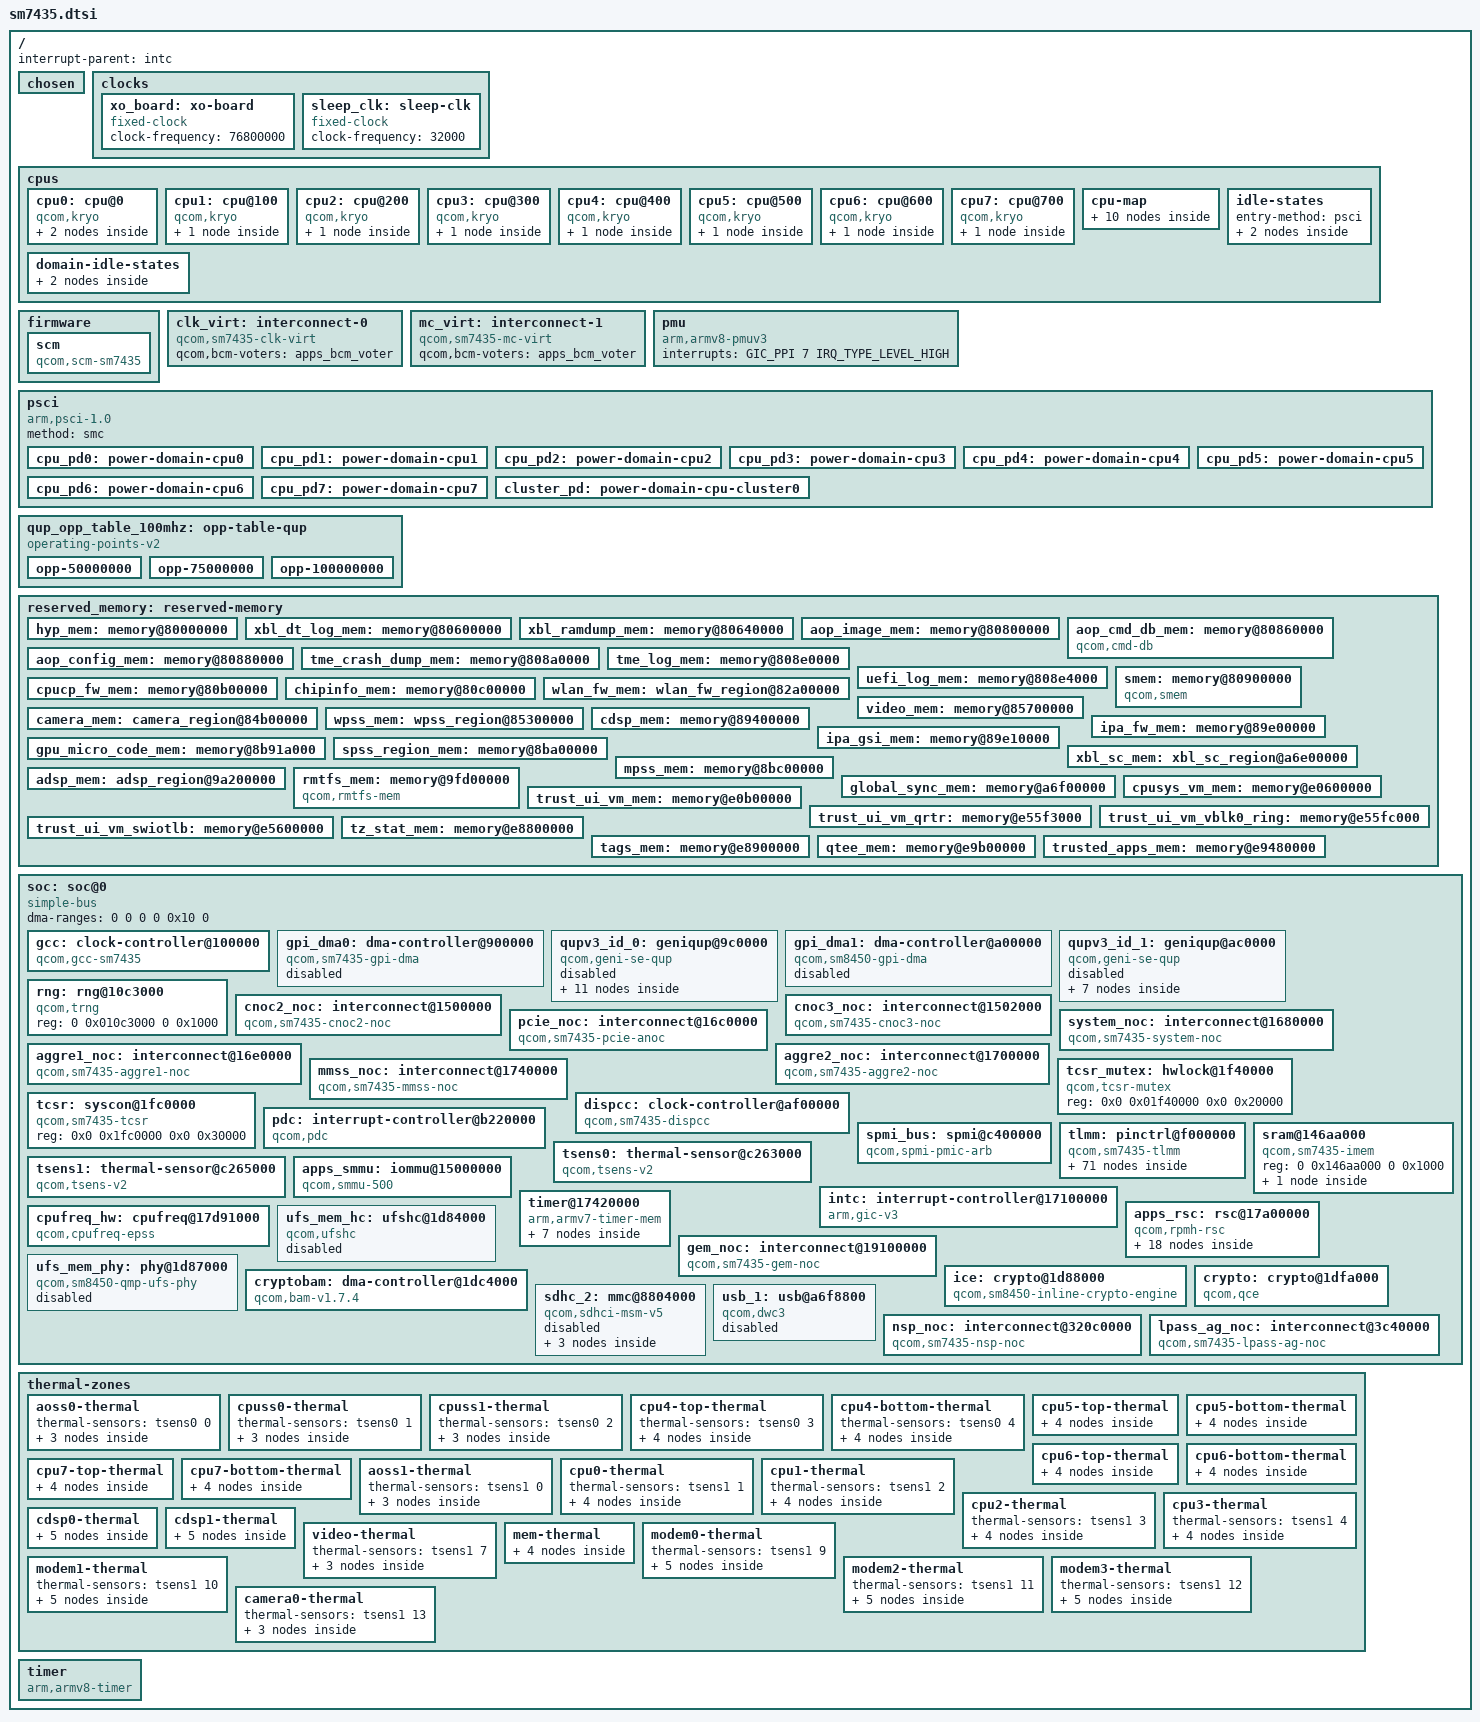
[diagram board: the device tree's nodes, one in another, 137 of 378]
// SPDX-License-Identifier: BSD-3-Clause
/*
 * Copyright (c) 2025 Artur Weber <aweber.kernel@gmail.com>
 */

#include <dt-bindings/interrupt-controller/arm-gic.h>
#include <dt-bindings/clock/qcom,gcc-sm7435.h>
#include <dt-bindings/clock/qcom,rpmh.h>
#include <dt-bindings/clock/qcom,sm7435-dispcc.h>
#include <dt-bindings/gpio/gpio.h>
#include <dt-bindings/mailbox/qcom-ipcc.h>
#include <dt-bindings/power/qcom,rpmhpd.h>
#include <dt-bindings/power/qcom-rpmpd.h>
#include <dt-bindings/interconnect/qcom,icc.h>
#include <dt-bindings/interconnect/qcom,sm7435.h>
#include <dt-bindings/soc/qcom,rpmh-rsc.h>
#include <dt-bindings/firmware/qcom,scm.h>
#include <dt-bindings/dma/qcom-gpi.h>

/ {
	interrupt-parent = <&intc>;

	#address-cells = <2>;
	#size-cells = <2>;

	chosen { };

	clocks {
		xo_board: xo-board {
			compatible = "fixed-clock";
			#clock-cells = <0>;
			clock-frequency = <76800000>;
		};

		sleep_clk: sleep-clk {
			compatible = "fixed-clock";
			#clock-cells = <0>;
			clock-frequency = <32000>; // TODO: 32764?
		};
	};

	cpus {
		#address-cells = <2>;
		#size-cells = <0>;

		// TODO: cache-unified? Should be fine but drop if it causes problems
		cpu0: cpu@0 {
			device_type = "cpu";
			compatible = "qcom,kryo";
			reg = <0x0 0x0>;
			enable-method = "psci";
			next-level-cache = <&l2_0>;
			power-domains = <&cpu_pd0>;
			power-domain-names = "psci";
			qcom,freq-domain = <&cpufreq_hw 0>;
			#cooling-cells = <2>;
			clocks = <&cpufreq_hw 0>;
			l2_0: l2-cache {
				compatible = "cache";
				cache-level = <2>;
				cache-unified;
				next-level-cache = <&l3_0>;
				l3_0: l3-cache {
					compatible = "cache";
					cache-level = <3>;
					cache-unified;
				};
			};
		};

		cpu1: cpu@100 {
			device_type = "cpu";
			compatible = "qcom,kryo";
			reg = <0x0 0x100>;
			enable-method = "psci";
			next-level-cache = <&l2_100>;
			power-domains = <&cpu_pd1>;
			power-domain-names = "psci";
			qcom,freq-domain = <&cpufreq_hw 0>;
			#cooling-cells = <2>;
			clocks = <&cpufreq_hw 0>;
			l2_100: l2-cache {
				compatible = "cache";
				cache-level = <2>;
				cache-unified;
				next-level-cache = <&l3_0>;
			};
		};

		cpu2: cpu@200 {
			device_type = "cpu";
			compatible = "qcom,kryo";
			reg = <0x0 0x200>;
			enable-method = "psci";
			next-level-cache = <&l2_200>;
			power-domains = <&cpu_pd2>;
			power-domain-names = "psci";
			qcom,freq-domain = <&cpufreq_hw 0>;
			#cooling-cells = <2>;
			clocks = <&cpufreq_hw 0>;
			l2_200: l2-cache {
				compatible = "cache";
				cache-level = <2>;
				cache-unified;
				next-level-cache = <&l3_0>;
			};
		};

		cpu3: cpu@300 {
			device_type = "cpu";
			compatible = "qcom,kryo";
			reg = <0x0 0x300>;
			enable-method = "psci";
			next-level-cache = <&l2_300>;
			power-domains = <&cpu_pd3>;
			power-domain-names = "psci";
			qcom,freq-domain = <&cpufreq_hw 0>;
			#cooling-cells = <2>;
			clocks = <&cpufreq_hw 0>;
			l2_300: l2-cache {
				compatible = "cache";
				cache-level = <2>;
				cache-unified;
				next-level-cache = <&l3_0>;
			};
		};

		cpu4: cpu@400 {
			device_type = "cpu";
			compatible = "qcom,kryo";
			reg = <0x0 0x400>;
			enable-method = "psci";
			next-level-cache = <&l2_400>;
			power-domains = <&cpu_pd4>;
			power-domain-names = "psci";
			qcom,freq-domain = <&cpufreq_hw 1>;
			#cooling-cells = <2>;
			clocks = <&cpufreq_hw 1>;
			l2_400: l2-cache {
				compatible = "cache";
				cache-level = <2>;
				cache-unified;
				next-level-cache = <&l3_0>;
			};
		};

		cpu5: cpu@500 {
			device_type = "cpu";
			compatible = "qcom,kryo";
			reg = <0x0 0x500>;
			enable-method = "psci";
			next-level-cache = <&l2_500>;
			power-domains = <&cpu_pd5>;
			power-domain-names = "psci";
			qcom,freq-domain = <&cpufreq_hw 1>;
			#cooling-cells = <2>;
			clocks = <&cpufreq_hw 1>;
			l2_500: l2-cache {
				compatible = "cache";
				cache-level = <2>;
				cache-unified;
				next-level-cache = <&l3_0>;
			};
		};

		cpu6: cpu@600 {
			device_type = "cpu";
			compatible = "qcom,kryo";
			reg = <0x0 0x600>;
			enable-method = "psci";
			next-level-cache = <&l2_600>;
			power-domains = <&cpu_pd6>;
			power-domain-names = "psci";
			qcom,freq-domain = <&cpufreq_hw 1>;
			#cooling-cells = <2>;
			clocks = <&cpufreq_hw 1>;
			l2_600: l2-cache {
				compatible = "cache";
				cache-level = <2>;
				cache-unified;
				next-level-cache = <&l3_0>;
			};
		};

		cpu7: cpu@700 {
			device_type = "cpu";
			compatible = "qcom,kryo";
			reg = <0x0 0x700>;
			enable-method = "psci";
			next-level-cache = <&l2_700>;
			power-domains = <&cpu_pd7>;
			power-domain-names = "psci";
			qcom,freq-domain = <&cpufreq_hw 2>;
			#cooling-cells = <2>;
			clocks = <&cpufreq_hw 2>;
			l2_700: l2-cache {
				compatible = "cache";
				cache-level = <2>;
				cache-unified;
				next-level-cache = <&l3_0>;
			};
		};

		cpu-map {
			cluster0 {
				core0 {
					cpu = <&cpu0>;
				};

				core1 {
					cpu = <&cpu1>;
				};

				core2 {
					cpu = <&cpu2>;
				};

				core3 {
					cpu = <&cpu3>;
				};
			};

			cluster1 {
				core4 {
					cpu = <&cpu4>;
				};

				core5 {
					cpu = <&cpu5>;
				};

				core6 {
					cpu = <&cpu6>;
				};

				core7 {
					cpu = <&cpu7>;
				};
			};
		};

		idle-states {
			entry-method = "psci";
			// TODO - untested, they are in the DTSI but aren't hooked up to anything
			little_cpu_sleep_0: cpu-sleep-0-0 {
				compatible = "arm,idle-state";
				idle-state-name = "silver-rail-power-collapse";
				arm,psci-suspend-param = <0x40000004>;
				entry-latency-us = <800>;
				exit-latency-us = <750>;
				min-residency-us = <4090>;
				local-timer-stop;
			};

			big_cpu_sleep_0: cpu-sleep-1-0 {
				compatible = "arm,idle-state";
				idle-state-name = "gold-rail-power-collapse";
				arm,psci-suspend-param = <0x40000004>;
				entry-latency-us = <600>;
				exit-latency-us = <1550>;
				min-residency-us = <4791>;
				local-timer-stop;
			};
		};

		domain-idle-states {
			cluster_sleep_0: cluster-sleep-0 {
				compatible = "domain-idle-state";
				arm,psci-suspend-param = <0x41000044>;
				entry-latency-us = <1050>;
				exit-latency-us = <2500>;
				min-residency-us = <5309>;
			};

			// TODO: called CX_RET in downstream, not sure if it's the one
			cluster_sleep_1: cluster-sleep-1 {
				compatible = "domain-idle-state";
				arm,psci-suspend-param = <0x41003344>;
				entry-latency-us = <1561>;
				exit-latency-us = <2801>;
				min-residency-us = <8550>;
			};
		};
	};

	firmware {
		scm: scm {
			compatible = "qcom,scm-sm7435", "qcom,scm";
			qcom,dload-mode = <&tcsr 0x13000>;
			interconnects = <&aggre2_noc MASTER_CRYPTO 0 &mc_virt SLAVE_EBI1 0>;
			#reset-cells = <1>;
		};
	};

	clk_virt: interconnect-0 {
		compatible = "qcom,sm7435-clk-virt";
		#interconnect-cells = <2>;
		qcom,bcm-voters = <&apps_bcm_voter>;
	};

	mc_virt: interconnect-1 {
		compatible = "qcom,sm7435-mc-virt";
		#interconnect-cells = <2>;
		qcom,bcm-voters = <&apps_bcm_voter>;
	};

	pmu {
		compatible = "arm,armv8-pmuv3";
		interrupts = <GIC_PPI 7 IRQ_TYPE_LEVEL_HIGH>;
	};

	psci {
		compatible = "arm,psci-1.0";
		method = "smc";


		cpu_pd0: power-domain-cpu0 {
			#power-domain-cells = <0>;
			power-domains = <&cluster_pd>;
			domain-idle-states = <&little_cpu_sleep_0>;
		};

		cpu_pd1: power-domain-cpu1 {
			#power-domain-cells = <0>;
			power-domains = <&cluster_pd>;
			domain-idle-states = <&little_cpu_sleep_0>;
		};

		cpu_pd2: power-domain-cpu2 {
			#power-domain-cells = <0>;
			power-domains = <&cluster_pd>;
			domain-idle-states = <&little_cpu_sleep_0>;
		};

		cpu_pd3: power-domain-cpu3 {
			#power-domain-cells = <0>;
			power-domains = <&cluster_pd>;
			domain-idle-states = <&little_cpu_sleep_0>;
		};

		cpu_pd4: power-domain-cpu4 {
			#power-domain-cells = <0>;
			power-domains = <&cluster_pd>;
			domain-idle-states = <&big_cpu_sleep_0>;
		};

		cpu_pd5: power-domain-cpu5 {
			#power-domain-cells = <0>;
			power-domains = <&cluster_pd>;
			domain-idle-states = <&big_cpu_sleep_0>;
		};

		cpu_pd6: power-domain-cpu6 {
			#power-domain-cells = <0>;
			power-domains = <&cluster_pd>;
			domain-idle-states = <&big_cpu_sleep_0>;
		};

		cpu_pd7: power-domain-cpu7 {
			#power-domain-cells = <0>;
			power-domains = <&cluster_pd>;
			domain-idle-states = <&big_cpu_sleep_0>;
		};

		cluster_pd: power-domain-cpu-cluster0 {
			#power-domain-cells = <0>;
			domain-idle-states = <&cluster_sleep_0>, <&cluster_sleep_1>;
		};
	};

	qup_opp_table_100mhz: opp-table-qup {
		compatible = "operating-points-v2";

		opp-50000000 {
			opp-hz = /bits/ 64 <50000000>;
			required-opps = <&rpmhpd_opp_min_svs>;
		};

		opp-75000000 {
			opp-hz = /bits/ 64 <75000000>;
			required-opps = <&rpmhpd_opp_low_svs>;
		};

		opp-100000000 {
			opp-hz = /bits/ 64 <100000000>;
			required-opps = <&rpmhpd_opp_svs>;
		};
	};

	reserved_memory: reserved-memory {
		#address-cells = <2>;
		#size-cells = <2>;
		ranges;

		hyp_mem: memory@80000000 {
			reg = <0x0 0x80000000 0x0 0x600000>;
			no-map;
		};

		xbl_dt_log_mem: memory@80600000 {
			reg = <0x0 0x80600000 0x0 0x40000>;
			no-map;
		};

		xbl_ramdump_mem: memory@80640000 {
			reg = <0x0 0x80640000 0x0 0x180000>;
			no-map;
		};

		aop_image_mem: memory@80800000 {
			reg = <0x0 0x80800000 0x0 0x60000>;
			no-map;
		};

		aop_cmd_db_mem: memory@80860000 {
			compatible = "qcom,cmd-db";
			reg = <0x0 0x80860000 0x0 0x20000>;
			no-map;
		};

		aop_config_mem: memory@80880000 {
			reg = <0x0 0x80880000 0x0 0x20000>;
			no-map;
		};

		tme_crash_dump_mem: memory@808a0000 {
			reg = <0x0 0x808a0000 0x0 0x40000>;
			no-map;
		};

		tme_log_mem: memory@808e0000 {
			reg = <0x0 0x808e0000 0x0 0x4000>;
			no-map;
		};

		uefi_log_mem: memory@808e4000 {
			reg = <0x0 0x808e4000 0x0 0x10000>;
			no-map;
		};

		/* secdata region can be reused by apps */
		smem: memory@80900000 {
			compatible = "qcom,smem";
			reg = <0x0 0x80900000 0x0 0x200000>;
			hwlocks = <&tcsr_mutex 3>;
			no-map;
		};

		cpucp_fw_mem: memory@80b00000 {
			reg = <0x0 0x80b00000 0x0 0x100000>;
			no-map;
		};

		chipinfo_mem: memory@80c00000 {
			reg = <0x0 0x80c00000 0x0 0x1000>;
			no-map;
		};

		wlan_fw_mem: wlan_fw_region@82a00000 {
			reg = <0 0x82a00000 0 0xc00000>;
			no-map;
		};

		camera_mem: camera_region@84b00000 {
			no-map;
			reg = <0 0x84b00000 0 0x800000>;
		};

		wpss_mem: wpss_region@85300000 {
			no-map;
			reg = <0 0x85300000 0 0x1900000>;
		};

		video_mem: memory@85700000 {
			reg = <0x0 0x85700000 0x0 0x700000>;
			no-map;
		};

		cdsp_mem: memory@89400000 {
			reg = <0x0 0x89400000 0x0 0xa00000>;
			no-map;
		};

		ipa_fw_mem: memory@89e00000 {
			reg = <0x0 0x89e00000 0x0 0x10000>;
			no-map;
		};

		ipa_gsi_mem: memory@89e10000 {
			reg = <0 0x89e10000 0 0xa000>;
			no-map;
		};

		gpu_micro_code_mem: memory@8b91a000 {
			reg = <0x0 0x8b91a000 0x0 0x2000>;
			no-map;
		};

		spss_region_mem: memory@8ba00000 {
			reg = <0x0 0x8ba00000 0x0 0x180000>;
			no-map;
		};

		xbl_sc_mem: xbl_sc_region@a6e00000 {
			reg = <0 0xa6e00000 0 0x40000>;
			no-map;
		};

		mpss_mem: memory@8bc00000 {
			reg = <0x0 0x8bc00000 0x0 0x2c00000>;
			no-map;
		};

		adsp_mem: adsp_region@9a200000 {
			reg = <0 0x9a200000 0 0x2900000>;
			no-map;
		};

		rmtfs_mem: memory@9fd00000 {
			compatible = "qcom,rmtfs-mem";
			// todo no address in downstream dts
			reg = <0x0 0x9fd00000 0x0 0x280000>;
			no-map;

			qcom,client-id = <1>;
			qcom,vmid = <QCOM_SCM_VMID_MSS_MSA>;
		};

		global_sync_mem: memory@a6f00000 {
			reg = <0x0 0xa6f00000 0x0 0x100000>;
			no-map;
		};

		/* Linux kernel image is loaded at 0xa0000000 */

		cpusys_vm_mem: memory@e0600000 {
			reg = <0x0 0xe0600000 0x0 0x400000>;
			no-map;
		};

		trust_ui_vm_mem: memory@e0b00000 {
			reg = <0x0 0xe0b00000 0x0 0x100000>; // todo sm8450 has diff size
			no-map;
		};

		trust_ui_vm_qrtr: memory@e55f3000 {
			reg = <0x0 0xe55f3000 0x0 0x9000>;
			no-map;
		};

		trust_ui_vm_vblk0_ring: memory@e55fc000 {
			reg = <0x0 0xe55fc000 0x0 0x4000>;
			no-map;
		};

		trust_ui_vm_swiotlb: memory@e5600000 {
			reg = <0x0 0xe5600000 0x0 0x100000>;
			no-map;
		};

		tz_stat_mem: memory@e8800000 {
			reg = <0x0 0xe8800000 0x0 0x100000>;
			no-map;
		};

		tags_mem: memory@e8900000 {
			reg = <0x0 0xe8900000 0x0 0x680000>;
			no-map;
		};

		qtee_mem: memory@e9b00000 {
			reg = <0x0 0xe9b00000 0x0 0x500000>;
			no-map;
		};

		trusted_apps_mem: memory@e9480000 {
			reg = <0x0 0xe9480000 0x0 0x1200000>;
			no-map;
		};
	};

	soc: soc@0 {
		#address-cells = <2>;
		#size-cells = <2>;
		ranges = <0 0 0 0 0x10 0>;
		dma-ranges = <0 0 0 0 0x10 0>;
		compatible = "simple-bus";

		gcc: clock-controller@100000 {
			compatible = "qcom,gcc-sm7435";
			reg = <0x0 0x00100000 0x0 0x1f4200>;
			#clock-cells = <1>;
			#reset-cells = <1>;
			#power-domain-cells = <1>;
			clocks = <&rpmhcc RPMH_CXO_CLK>,
				 <&sleep_clk>,
				 <&ufs_mem_phy 0>,
				 <&ufs_mem_phy 1>,
				 <&ufs_mem_phy 2>;
			clock-names = "bi_tcxo",
				      "sleep_clk",
				      "ufs_phy_rx_symbol_0_clk",
				      "ufs_phy_rx_symbol_1_clk",
				      "ufs_phy_tx_symbol_0_clk";
		};

		gpi_dma0: dma-controller@900000 {
			// TODO: might need to drop the 2nd compatible
			compatible = "qcom,sm7435-gpi-dma", "qcom,sm6350-gpi-dma";
			#dma-cells = <3>;
			reg = <0 0x00900000 0 0x60000>;
			interrupts = <GIC_SPI 244 IRQ_TYPE_LEVEL_HIGH>,
				     <GIC_SPI 245 IRQ_TYPE_LEVEL_HIGH>,
				     <GIC_SPI 246 IRQ_TYPE_LEVEL_HIGH>,
				     <GIC_SPI 247 IRQ_TYPE_LEVEL_HIGH>,
				     <GIC_SPI 248 IRQ_TYPE_LEVEL_HIGH>,
				     <GIC_SPI 249 IRQ_TYPE_LEVEL_HIGH>,
				     <GIC_SPI 250 IRQ_TYPE_LEVEL_HIGH>,
				     <GIC_SPI 251 IRQ_TYPE_LEVEL_HIGH>,
				     <GIC_SPI 252 IRQ_TYPE_LEVEL_HIGH>,
				     <GIC_SPI 253 IRQ_TYPE_LEVEL_HIGH>,
				     <GIC_SPI 254 IRQ_TYPE_LEVEL_HIGH>,
				     <GIC_SPI 255 IRQ_TYPE_LEVEL_HIGH>;
			dma-channels = <12>;
			dma-channel-mask = <0x7e>;
			iommus = <&apps_smmu 0x176 0x0>;
			status = "disabled";
		};

		qupv3_id_0: geniqup@9c0000 {
			compatible = "qcom,geni-se-qup";
			reg = <0x0 0x009c0000 0x0 0x2000>;
			clock-names = "m-ahb", "s-ahb";
			clocks = <&gcc GCC_QUPV3_WRAP_0_M_AHB_CLK>,
				 <&gcc GCC_QUPV3_WRAP_0_S_AHB_CLK>;
			iommus = <&apps_smmu 0x163 0x0>;
			interconnects = <&clk_virt MASTER_QUP_CORE_0 0 &clk_virt SLAVE_QUP_CORE_0 0>;
			interconnect-names = "qup-core";
			#address-cells = <2>;
			#size-cells = <2>;
			ranges;
			status = "disabled";

			i2c0: i2c@980000 {
				compatible = "qcom,geni-i2c";
				reg = <0x0 0x00980000 0x0 0x4000>;
				clock-names = "se";
				clocks = <&gcc GCC_QUPV3_WRAP0_S0_CLK>;
				pinctrl-names = "default";
				pinctrl-0 = <&qup_i2c0_data_clk>;
				interrupts = <GIC_SPI 601 IRQ_TYPE_LEVEL_HIGH>;
				#address-cells = <1>;
				#size-cells = <0>;
				interconnects = <&clk_virt MASTER_QUP_CORE_0 0 &clk_virt SLAVE_QUP_CORE_0 0>,
						<&system_noc MASTER_A2NOC_SNOC 0 &gem_noc SLAVE_LLCC 0>,
						<&aggre2_noc MASTER_QUP_0 0 &mc_virt SLAVE_EBI1 0>;
				interconnect-names = "qup-core", "qup-config", "qup-memory";
				dmas = <&gpi_dma0 0 0 QCOM_GPI_I2C>,
				       <&gpi_dma0 1 0 QCOM_GPI_I2C>;
				dma-names = "tx", "rx";
				status = "disabled";
			};

			spi0: spi@980000 {
				compatible = "qcom,geni-spi";
				reg = <0x0 0x00980000 0x0 0x4000>;
				clock-names = "se";
				clocks = <&gcc GCC_QUPV3_WRAP0_S0_CLK>;
				interrupts = <GIC_SPI 601 IRQ_TYPE_LEVEL_HIGH>;
				pinctrl-names = "default";
				pinctrl-0 = <&qup_spi0_data_clk>, <&qup_spi0_cs>;
				power-domains = <&rpmhpd RPMHPD_CX>;
				operating-points-v2 = <&qup_opp_table_100mhz>;
				interconnects = <&clk_virt MASTER_QUP_CORE_0 0 &clk_virt SLAVE_QUP_CORE_0 0>,
						<&system_noc MASTER_A2NOC_SNOC 0 &gem_noc SLAVE_LLCC 0>,
						<&aggre2_noc MASTER_QUP_0 0 &mc_virt SLAVE_EBI1 0>;
				interconnect-names = "qup-core", "qup-config", "qup-memory";
				dmas = <&gpi_dma0 0 0 QCOM_GPI_SPI>,
				       <&gpi_dma0 1 0 QCOM_GPI_SPI>;
				dma-names = "tx", "rx";
				#address-cells = <1>;
				#size-cells = <0>;
				status = "disabled";
			};

			i2c1: i2c@984000 {
				compatible = "qcom,geni-i2c";
				reg = <0x0 0x00984000 0x0 0x4000>;
				clock-names = "se";
				clocks = <&gcc GCC_QUPV3_WRAP0_S1_CLK>;
				pinctrl-names = "default";
				pinctrl-0 = <&qup_i2c1_data_clk>;
				interrupts = <GIC_SPI 602 IRQ_TYPE_LEVEL_HIGH>;
				#address-cells = <1>;
				#size-cells = <0>;
				interconnects = <&clk_virt MASTER_QUP_CORE_0 0 &clk_virt SLAVE_QUP_CORE_0 0>,
						<&system_noc MASTER_A2NOC_SNOC 0 &gem_noc SLAVE_LLCC 0>,
						<&aggre2_noc MASTER_QUP_0 0 &mc_virt SLAVE_EBI1 0>;
				interconnect-names = "qup-core", "qup-config", "qup-memory";
				dmas = <&gpi_dma0 0 1 QCOM_GPI_I2C>,
				       <&gpi_dma0 1 1 QCOM_GPI_I2C>;
				dma-names = "tx", "rx";
				status = "disabled";
			};

			spi1: spi@984000 {
				compatible = "qcom,geni-spi";
				reg = <0x0 0x00984000 0x0 0x4000>;
				clock-names = "se";
				clocks = <&gcc GCC_QUPV3_WRAP0_S1_CLK>;
				interrupts = <GIC_SPI 602 IRQ_TYPE_LEVEL_HIGH>;
				pinctrl-names = "default";
				pinctrl-0 = <&qup_spi1_data_clk>, <&qup_spi1_cs>;
				interconnects = <&clk_virt MASTER_QUP_CORE_0 0 &clk_virt SLAVE_QUP_CORE_0 0>,
						<&system_noc MASTER_A2NOC_SNOC 0 &gem_noc SLAVE_LLCC 0>,
						<&aggre2_noc MASTER_QUP_0 0 &mc_virt SLAVE_EBI1 0>;
				interconnect-names = "qup-core", "qup-config", "qup-memory";
				dmas = <&gpi_dma0 0 1 QCOM_GPI_SPI>,
				       <&gpi_dma0 1 1 QCOM_GPI_SPI>;
				dma-names = "tx", "rx";
				#address-cells = <1>;
				#size-cells = <0>;
				status = "disabled";
			};

			i2c2: i2c@988000 {
				compatible = "qcom,geni-i2c";
				reg = <0x0 0x00988000 0x0 0x4000>;
				clock-names = "se";
				clocks = <&gcc GCC_QUPV3_WRAP0_S2_CLK>;
				pinctrl-names = "default";
				pinctrl-0 = <&qup_i2c2_data_clk>;
				interrupts = <GIC_SPI 603 IRQ_TYPE_LEVEL_HIGH>;
				#address-cells = <1>;
				#size-cells = <0>;
				interconnects = <&clk_virt MASTER_QUP_CORE_0 0 &clk_virt SLAVE_QUP_CORE_0 0>,
						<&system_noc MASTER_A2NOC_SNOC 0 &gem_noc SLAVE_LLCC 0>,
						<&aggre2_noc MASTER_QUP_0 0 &mc_virt SLAVE_EBI1 0>;
				interconnect-names = "qup-core", "qup-config", "qup-memory";
				dmas = <&gpi_dma0 0 2 QCOM_GPI_I2C>,
				       <&gpi_dma0 1 2 QCOM_GPI_I2C>;
				dma-names = "tx", "rx";
				status = "disabled";
			};

			spi2: spi@988000 {
				compatible = "qcom,geni-spi";
				reg = <0x0 0x00988000 0x0 0x4000>;
				clock-names = "se";
				clocks = <&gcc GCC_QUPV3_WRAP0_S2_CLK>;
				interrupts = <GIC_SPI 603 IRQ_TYPE_LEVEL_HIGH>;
				pinctrl-names = "default";
				pinctrl-0 = <&qup_spi2_data_clk>, <&qup_spi2_cs>;
				interconnects = <&clk_virt MASTER_QUP_CORE_0 0 &clk_virt SLAVE_QUP_CORE_0 0>,
						<&system_noc MASTER_A2NOC_SNOC 0 &gem_noc SLAVE_LLCC 0>,
						<&aggre2_noc MASTER_QUP_0 0 &mc_virt SLAVE_EBI1 0>;
				interconnect-names = "qup-core", "qup-config", "qup-memory";
				dmas = <&gpi_dma0 0 2 QCOM_GPI_SPI>,
				       <&gpi_dma0 1 2 QCOM_GPI_SPI>;
				dma-names = "tx", "rx";
				#address-cells = <1>;
				#size-cells = <0>;
				status = "disabled";
			};

			uart3: serial@98c000 {
				compatible = "qcom,geni-debug-uart";
				reg = <0 0x0098c000 0 0x4000>;
				clock-names = "se";
				clocks = <&gcc GCC_QUPV3_WRAP0_S3_CLK>;
				pinctrl-names = "default";
				pinctrl-0 = <&qup_uart3_tx>, <&qup_uart3_rx>;
				interrupts = <GIC_SPI 608 IRQ_TYPE_LEVEL_HIGH>;
				// TODO interconnects?
				interconnects = <&clk_virt MASTER_QUP_CORE_1 QCOM_ICC_TAG_ALWAYS
						 &clk_virt SLAVE_QUP_CORE_1 QCOM_ICC_TAG_ALWAYS>,
						<&gem_noc MASTER_APPSS_PROC QCOM_ICC_TAG_ALWAYS
						 &cnoc2_noc SLAVE_QUP_1 QCOM_ICC_TAG_ALWAYS>;
				interconnect-names = "qup-core",
						     "qup-config";
				status = "disabled";
			};

			i2c4: i2c@990000 {
				compatible = "qcom,geni-i2c";
				reg = <0x0 0x00990000 0x0 0x4000>;
				clock-names = "se";
				clocks = <&gcc GCC_QUPV3_WRAP0_S4_CLK>;
				pinctrl-names = "default";
				pinctrl-0 = <&qup_i2c4_data_clk>;
				interrupts = <GIC_SPI 605 IRQ_TYPE_LEVEL_HIGH>;
				#address-cells = <1>;
				#size-cells = <0>;
				interconnects = <&clk_virt MASTER_QUP_CORE_0 0 &clk_virt SLAVE_QUP_CORE_0 0>,
						<&system_noc MASTER_A2NOC_SNOC 0 &gem_noc SLAVE_LLCC 0>,
						<&aggre2_noc MASTER_QUP_0 0 &mc_virt SLAVE_EBI1 0>;
				interconnect-names = "qup-core", "qup-config", "qup-memory";
				dmas = <&gpi_dma0 0 4 QCOM_GPI_I2C>,
				       <&gpi_dma0 1 4 QCOM_GPI_I2C>;
				dma-names = "tx", "rx";
				status = "disabled";
			};

			spi4: spi@990000 {
				compatible = "qcom,geni-spi";
				reg = <0x0 0x00990000 0x0 0x4000>;
				clock-names = "se";
				clocks = <&gcc GCC_QUPV3_WRAP0_S4_CLK>;
				interrupts = <GIC_SPI 605 IRQ_TYPE_LEVEL_HIGH>;
				pinctrl-names = "default";
				pinctrl-0 = <&qup_spi4_data_clk>, <&qup_spi4_cs>;
				power-domains = <&rpmhpd RPMHPD_CX>;
				operating-points-v2 = <&qup_opp_table_100mhz>;
				interconnects = <&clk_virt MASTER_QUP_CORE_0 0 &clk_virt SLAVE_QUP_CORE_0 0>,
						<&system_noc MASTER_A2NOC_SNOC 0 &gem_noc SLAVE_LLCC 0>,
						<&aggre2_noc MASTER_QUP_0 0 &mc_virt SLAVE_EBI1 0>;
				interconnect-names = "qup-core", "qup-config", "qup-memory";
				dmas = <&gpi_dma0 0 4 QCOM_GPI_SPI>,
				       <&gpi_dma0 1 4 QCOM_GPI_SPI>;
				dma-names = "tx", "rx";
				#address-cells = <1>;
				#size-cells = <0>;
				status = "disabled";
			};

			i2c5: i2c@994000 {
				compatible = "qcom,geni-i2c";
				reg = <0x0 0x00994000 0x0 0x4000>;
				clock-names = "se";
				clocks = <&gcc GCC_QUPV3_WRAP0_S5_CLK>;
				pinctrl-names = "default";
				pinctrl-0 = <&qup_i2c5_data_clk>;
				interrupts = <GIC_SPI 606 IRQ_TYPE_LEVEL_HIGH>;
				#address-cells = <1>;
				#size-cells = <0>;
				interconnects = <&clk_virt MASTER_QUP_CORE_0 0 &clk_virt SLAVE_QUP_CORE_0 0>,
						<&system_noc MASTER_A2NOC_SNOC 0 &gem_noc SLAVE_LLCC 0>,
						<&aggre2_noc MASTER_QUP_0 0 &mc_virt SLAVE_EBI1 0>;
				interconnect-names = "qup-core", "qup-config", "qup-memory";
				dmas = <&gpi_dma0 0 5 QCOM_GPI_I2C>,
				       <&gpi_dma0 1 5 QCOM_GPI_I2C>;
				dma-names = "tx", "rx";
				status = "disabled";
			};

			spi5: spi@994000 {
				compatible = "qcom,geni-spi";
				reg = <0x0 0x00994000 0x0 0x4000>;
				clock-names = "se";
				clocks = <&gcc GCC_QUPV3_WRAP0_S5_CLK>;
				interrupts = <GIC_SPI 606 IRQ_TYPE_LEVEL_HIGH>;
				pinctrl-names = "default";
				pinctrl-0 = <&qup_spi5_data_clk>, <&qup_spi5_cs>;
				interconnects = <&clk_virt MASTER_QUP_CORE_0 0 &clk_virt SLAVE_QUP_CORE_0 0>,
						<&system_noc MASTER_A2NOC_SNOC 0 &gem_noc SLAVE_LLCC 0>,
						<&aggre2_noc MASTER_QUP_0 0 &mc_virt SLAVE_EBI1 0>;
				interconnect-names = "qup-core", "qup-config", "qup-memory";
				dmas = <&gpi_dma0 0 5 QCOM_GPI_SPI>,
				       <&gpi_dma0 1 5 QCOM_GPI_SPI>;
				dma-names = "tx", "rx";
				#address-cells = <1>;
				#size-cells = <0>;
				status = "disabled";
			};
		};

		gpi_dma1: dma-controller@a00000 {
			compatible = "qcom,sm8450-gpi-dma", "qcom,sm6350-gpi-dma";
			#dma-cells = <3>;
			reg = <0 0x00a00000 0 0x60000>;
			interrupts = <GIC_SPI 279 IRQ_TYPE_LEVEL_HIGH>,
				     <GIC_SPI 280 IRQ_TYPE_LEVEL_HIGH>,
				     <GIC_SPI 281 IRQ_TYPE_LEVEL_HIGH>,
				     <GIC_SPI 282 IRQ_TYPE_LEVEL_HIGH>,
				     <GIC_SPI 283 IRQ_TYPE_LEVEL_HIGH>,
				     <GIC_SPI 284 IRQ_TYPE_LEVEL_HIGH>,
				     <GIC_SPI 293 IRQ_TYPE_LEVEL_HIGH>,
				     <GIC_SPI 294 IRQ_TYPE_LEVEL_HIGH>,
				     <GIC_SPI 295 IRQ_TYPE_LEVEL_HIGH>,
				     <GIC_SPI 296 IRQ_TYPE_LEVEL_HIGH>,
				     <GIC_SPI 297 IRQ_TYPE_LEVEL_HIGH>,
				     <GIC_SPI 298 IRQ_TYPE_LEVEL_HIGH>;
			dma-channels = <12>;
			dma-channel-mask = <0x7e>;
			iommus = <&apps_smmu 0x416 0x0>;
			status = "disabled";
		};

		qupv3_id_1: geniqup@ac0000 {
			compatible = "qcom,geni-se-qup";
			reg = <0x0 0x00ac0000 0x0 0x6000>;
			clock-names = "m-ahb", "s-ahb";
			clocks = <&gcc GCC_QUPV3_WRAP_1_M_AHB_CLK>,
				 <&gcc GCC_QUPV3_WRAP_1_S_AHB_CLK>;
			iommus = <&apps_smmu 0x403 0x0>;
			interconnects = <&clk_virt MASTER_QUP_CORE_1 0 &clk_virt SLAVE_QUP_CORE_1 0>;
			interconnect-names = "qup-core";
			#address-cells = <2>;
			#size-cells = <2>;
			ranges;
			status = "disabled";

			i2c6: i2c@a80000 {
				compatible = "qcom,geni-i2c";
				reg = <0x0 0x00a80000 0x0 0x4000>;
				clock-names = "se";
				clocks = <&gcc GCC_QUPV3_WRAP1_S0_CLK>;
				pinctrl-names = "default";
				pinctrl-0 = <&qup_i2c8_data_clk>;
				interrupts = <GIC_SPI 353 IRQ_TYPE_LEVEL_HIGH>;
				#address-cells = <1>;
				#size-cells = <0>;
				interconnects = <&clk_virt MASTER_QUP_CORE_1 0 &clk_virt SLAVE_QUP_CORE_1 0>,
						<&system_noc MASTER_A2NOC_SNOC 0 &gem_noc SLAVE_LLCC 0>,
						<&aggre2_noc MASTER_QUP_1 0 &mc_virt SLAVE_EBI1 0>;
				interconnect-names = "qup-core", "qup-config", "qup-memory";
				dmas = <&gpi_dma1 0 0 QCOM_GPI_I2C>,
				       <&gpi_dma1 1 0 QCOM_GPI_I2C>;
				dma-names = "tx", "rx";
				status = "disabled";
			};

			spi6: spi@a80000 {
				compatible = "qcom,geni-spi";
				reg = <0x0 0x00a80000 0x0 0x4000>;
				clock-names = "se";
				clocks = <&gcc GCC_QUPV3_WRAP1_S0_CLK>;
				interrupts = <GIC_SPI 353 IRQ_TYPE_LEVEL_HIGH>;
				pinctrl-names = "default";
				pinctrl-0 = <&qup_spi8_data_clk>, <&qup_spi8_cs>;
				interconnects = <&clk_virt MASTER_QUP_CORE_1 0 &clk_virt SLAVE_QUP_CORE_1 0>,
						<&system_noc MASTER_A2NOC_SNOC 0 &gem_noc SLAVE_LLCC 0>,
						<&aggre2_noc MASTER_QUP_1 0 &mc_virt SLAVE_EBI1 0>;
				interconnect-names = "qup-core", "qup-config", "qup-memory";
				dmas = <&gpi_dma1 0 0 QCOM_GPI_SPI>,
				       <&gpi_dma1 1 0 QCOM_GPI_SPI>;
				dma-names = "tx", "rx";
				#address-cells = <1>;
				#size-cells = <0>;
				status = "disabled";
			};

			i2c7: i2c@a84000 {
				compatible = "qcom,geni-i2c";
				reg = <0x0 0x00a84000 0x0 0x4000>;
				clock-names = "se";
				clocks = <&gcc GCC_QUPV3_WRAP1_S1_CLK>;
				pinctrl-names = "default";
				pinctrl-0 = <&qup_i2c9_data_clk>;
				interrupts = <GIC_SPI 354 IRQ_TYPE_LEVEL_HIGH>;
				#address-cells = <1>;
				#size-cells = <0>;
				interconnects = <&clk_virt MASTER_QUP_CORE_1 0 &clk_virt SLAVE_QUP_CORE_1 0>,
						<&system_noc MASTER_A2NOC_SNOC 0 &gem_noc SLAVE_LLCC 0>,
						<&aggre2_noc MASTER_QUP_1 0 &mc_virt SLAVE_EBI1 0>;
				interconnect-names = "qup-core", "qup-config", "qup-memory";
				dmas = <&gpi_dma1 0 1 QCOM_GPI_I2C>,
				       <&gpi_dma1 1 1 QCOM_GPI_I2C>;
				dma-names = "tx", "rx";
				status = "disabled";
			};

			spi7: spi@a84000 {
				compatible = "qcom,geni-spi";
				reg = <0x0 0x00a84000 0x0 0x4000>;
				clock-names = "se";
				clocks = <&gcc GCC_QUPV3_WRAP1_S1_CLK>;
				interrupts = <GIC_SPI 354 IRQ_TYPE_LEVEL_HIGH>;
				pinctrl-names = "default";
				pinctrl-0 = <&qup_spi9_data_clk>, <&qup_spi9_cs>;
				interconnects = <&clk_virt MASTER_QUP_CORE_1 0 &clk_virt SLAVE_QUP_CORE_1 0>,
						<&system_noc MASTER_A2NOC_SNOC 0 &gem_noc SLAVE_LLCC 0>,
						<&aggre2_noc MASTER_QUP_1 0 &mc_virt SLAVE_EBI1 0>;
				interconnect-names = "qup-core", "qup-config", "qup-memory";
				dmas = <&gpi_dma1 0 1 QCOM_GPI_SPI>,
				       <&gpi_dma1 1 1 QCOM_GPI_SPI>;
				dma-names = "tx", "rx";
				#address-cells = <1>;
				#size-cells = <0>;
				status = "disabled";
			};

			i2c8: i2c@a88000 {
				compatible = "qcom,geni-i2c";
				reg = <0x0 0x00a88000 0x0 0x4000>;
				clock-names = "se";
				clocks = <&gcc GCC_QUPV3_WRAP1_S2_CLK>;
				pinctrl-names = "default";
				pinctrl-0 = <&qup_i2c10_data_clk>;
				interrupts = <GIC_SPI 355 IRQ_TYPE_LEVEL_HIGH>;
				#address-cells = <1>;
				#size-cells = <0>;
				interconnects = <&clk_virt MASTER_QUP_CORE_1 0 &clk_virt SLAVE_QUP_CORE_1 0>,
						<&system_noc MASTER_A2NOC_SNOC 0 &gem_noc SLAVE_LLCC 0>,
						<&aggre2_noc MASTER_QUP_1 0 &mc_virt SLAVE_EBI1 0>;
				interconnect-names = "qup-core", "qup-config", "qup-memory";
				dmas = <&gpi_dma1 0 2 QCOM_GPI_I2C>,
				       <&gpi_dma1 1 2 QCOM_GPI_I2C>;
				dma-names = "tx", "rx";
				status = "disabled";
			};

			spi8: spi@a88000 {
				compatible = "qcom,geni-spi";
				reg = <0x0 0x00a88000 0x0 0x4000>;
				clock-names = "se";
				clocks = <&gcc GCC_QUPV3_WRAP1_S2_CLK>;
				interrupts = <GIC_SPI 355 IRQ_TYPE_LEVEL_HIGH>;
				pinctrl-names = "default";
				pinctrl-0 = <&qup_spi10_data_clk>, <&qup_spi10_cs>;
				interconnects = <&clk_virt MASTER_QUP_CORE_1 0 &clk_virt SLAVE_QUP_CORE_1 0>,
						<&system_noc MASTER_A2NOC_SNOC 0 &gem_noc SLAVE_LLCC 0>,
						<&aggre2_noc MASTER_QUP_1 0 &mc_virt SLAVE_EBI1 0>;
				interconnect-names = "qup-core", "qup-config", "qup-memory";
				dmas = <&gpi_dma1 0 2 QCOM_GPI_SPI>,
				       <&gpi_dma1 1 2 QCOM_GPI_SPI>;
				dma-names = "tx", "rx";
				#address-cells = <1>;
				#size-cells = <0>;
				status = "disabled";
			};

			i2c9: i2c@a8c000 {
				compatible = "qcom,geni-i2c";
				reg = <0x0 0x00a8c000 0x0 0x4000>;
				clock-names = "se";
				clocks = <&gcc GCC_QUPV3_WRAP1_S3_CLK>;
				pinctrl-names = "default";
				pinctrl-0 = <&qup_i2c11_data_clk>;
				interrupts = <GIC_SPI 356 IRQ_TYPE_LEVEL_HIGH>;
				#address-cells = <1>;
				#size-cells = <0>;
				interconnects = <&clk_virt MASTER_QUP_CORE_1 0 &clk_virt SLAVE_QUP_CORE_1 0>,
						<&system_noc MASTER_A2NOC_SNOC 0 &gem_noc SLAVE_LLCC 0>,
						<&aggre2_noc MASTER_QUP_1 0 &mc_virt SLAVE_EBI1 0>;
				interconnect-names = "qup-core", "qup-config", "qup-memory";
				dmas = <&gpi_dma1 0 3 QCOM_GPI_I2C>,
				       <&gpi_dma1 1 3 QCOM_GPI_I2C>;
				dma-names = "tx", "rx";
				status = "disabled";
			};
		};

		rng: rng@10c3000 {
			compatible = "qcom,trng";
			reg = <0 0x010c3000 0 0x1000>;
		};

		cnoc2_noc: interconnect@1500000 {
			compatible = "qcom,sm7435-cnoc2-noc";
			reg = <0 0x01500000 0 0x1000>;
			#interconnect-cells = <2>;
			qcom,bcm-voters = <&apps_bcm_voter>;
		};

		cnoc3_noc: interconnect@1502000 {
			compatible = "qcom,sm7435-cnoc3-noc";
			reg = <0 0x01502000 0 0x1000>;
			#interconnect-cells = <2>;
			qcom,bcm-voters = <&apps_bcm_voter>;
		};

		system_noc: interconnect@1680000 {
			compatible = "qcom,sm7435-system-noc";
			reg = <0 0x01680000 0 0x1e200>;
			#interconnect-cells = <2>;
			qcom,bcm-voters = <&apps_bcm_voter>;
		};

		pcie_noc: interconnect@16c0000 {
			compatible = "qcom,sm7435-pcie-anoc";
			reg = <0 0x016c0000 0 0xe280>;
			#interconnect-cells = <2>;
			qcom,bcm-voters = <&apps_bcm_voter>;
		};

		aggre1_noc: interconnect@16e0000 {
			compatible = "qcom,sm7435-aggre1-noc";
			reg = <0 0x016e0000 0 0x1c080>;
			#interconnect-cells = <2>;
			clocks = <&gcc GCC_AGGRE_UFS_PHY_AXI_CLK>,
				 <&gcc GCC_AGGRE_USB3_PRIM_AXI_CLK>;
			qcom,bcm-voters = <&apps_bcm_voter>;
		};

		aggre2_noc: interconnect@1700000 {
			compatible = "qcom,sm7435-aggre2-noc";
			reg = <0 0x01700000 0 0x31080>;
			#interconnect-cells = <2>;
			qcom,bcm-voters = <&apps_bcm_voter>;
			clocks = <&gcc GCC_AGGRE_NOC_PCIE_0_AXI_CLK>,
				 <&gcc GCC_AGGRE_UFS_PHY_AXI_CLK>,
				 <&rpmhcc RPMH_IPA_CLK>;
		};

		mmss_noc: interconnect@1740000 {
			compatible = "qcom,sm7435-mmss-noc";
			reg = <0 0x01740000 0 0x1f080>;
			#interconnect-cells = <2>;
			qcom,bcm-voters = <&apps_bcm_voter>;
		};

		tcsr_mutex: hwlock@1f40000 {
			compatible = "qcom,tcsr-mutex";
			reg = <0x0 0x01f40000 0x0 0x20000>;
			#hwlock-cells = <1>;
		};

		tcsr: syscon@1fc0000 {
			compatible = "qcom,sm7435-tcsr", "syscon";
			reg = <0x0 0x1fc0000 0x0 0x30000>;
		};

		// TODO: GPU

		// TODO: USB

		// TODO: SLPI

		// TODO: Audio

		// TODO: MDSS

		dispcc: clock-controller@af00000 {
			compatible = "qcom,sm7435-dispcc";
			reg = <0 0x0af00000 0 0x20000>;
			clocks = <&rpmhcc RPMH_CXO_CLK>,
				 <&rpmhcc RPMH_CXO_CLK_A>,
				 <&gcc GCC_DISP_AHB_CLK>,
				 <&sleep_clk>,
				 // <&mdss_dsi0_phy 0>,
				 // <&mdss_dsi0_phy 1>,
				 <0>, /* dp1 */
				 <0>,
				 <0>, /* dp2 */
				 <0>,
				 <0>, /* dp3 */
				 <0>;
			power-domains = <&rpmhpd RPMHPD_MMCX>;
			required-opps = <&rpmhpd_opp_low_svs>;
			#clock-cells = <1>;
			#reset-cells = <1>;
			#power-domain-cells = <1>;
		};

		pdc: interrupt-controller@b220000 {
			compatible = "qcom,pdc";
			reg = <0 0x0b220000 0 0x30000>, <0 0x174000f0 0 0x64>;
			qcom,pdc-ranges = <0 480 94>, <94 609 31>, <125 63 1>,
					  <126 716 12>;
			#interrupt-cells = <2>;
			interrupt-parent = <&intc>;
			interrupt-controller;
		};

		spmi_bus: spmi@c400000 {
			compatible = "qcom,spmi-pmic-arb";
			reg = <0 0x0c400000 0 0x00003000>,
			      <0 0x0c500000 0 0x00400000>,
			      <0 0x0c440000 0 0x00080000>,
			      <0 0x0c4c0000 0 0x00010000>,
			      <0 0x0c42d000 0 0x00010000>;
			reg-names = "core",
				    "chnls",
				    "obsrvr",
				    "intr",
				    "cnfg";
			interrupt-names = "periph_irq";
			interrupts-extended = <&pdc 1 IRQ_TYPE_LEVEL_HIGH>;
			qcom,ee = <0>;
			qcom,channel = <0>;
			interrupt-controller;
			#interrupt-cells = <4>;
			#address-cells = <2>;
			#size-cells = <0>;
		};

		tlmm: pinctrl@f000000 {
			compatible = "qcom,sm7435-tlmm";
			reg = <0 0x0f000000 0 0x1000000>;
			interrupts = <GIC_SPI 208 IRQ_TYPE_LEVEL_HIGH>;
			gpio-controller;
			#gpio-cells = <2>;
			interrupt-controller;
			#interrupt-cells = <2>;
			gpio-ranges = <&tlmm 0 0 211>;
			wakeup-parent = <&pdc>;

			sdc2_default_state: sdc2-default-state {
				clk-pins {
					pins = "sdc2_clk";
					drive-strength = <16>;
					bias-disable;
				};

				cmd-pins {
					pins = "sdc2_cmd";
					drive-strength = <16>;
					bias-pull-up;
				};

				data-pins {
					pins = "sdc2_data";
					drive-strength = <16>;
					bias-pull-up;
				};
			};

			sdc2_sleep_state: sdc2-sleep-state {
				clk-pins {
					pins = "sdc2_clk";
					drive-strength = <2>;
					bias-disable;
				};

				cmd-pins {
					pins = "sdc2_cmd";
					drive-strength = <2>;
					bias-pull-up;
				};

				data-pins {
					pins = "sdc2_data";
					drive-strength = <2>;
					bias-pull-up;
				};
			};

			qup_i2c0_data_clk: qup-i2c0-data-clk-state {
				pins = "gpio0", "gpio1";
				function = "qup0";
			};

			qup_i2c1_data_clk: qup-i2c1-data-clk-state {
				pins = "gpio4", "gpio5";
				function = "qup1";
			};

			qup_i2c2_data_clk: qup-i2c2-data-clk-state {
				pins = "gpio8", "gpio9";
				function = "qup2";
			};

			qup_i2c3_data_clk: qup-i2c3-data-clk-state {
				pins = "gpio12", "gpio13";
				function = "qup3";
			};

			qup_i2c4_data_clk: qup-i2c4-data-clk-state {
				pins = "gpio16", "gpio17";
				function = "qup4";
			};

			qup_i2c5_data_clk: qup-i2c5-data-clk-state {
				pins = "gpio206", "gpio207";
				function = "qup5";
			};

			qup_i2c6_data_clk: qup-i2c6-data-clk-state {
				pins = "gpio20", "gpio21";
				function = "qup6";
			};

			qup_i2c8_data_clk: qup-i2c8-data-clk-state {
				pins = "gpio28", "gpio29";
				function = "qup8";
			};

			qup_i2c9_data_clk: qup-i2c9-data-clk-state {
				pins = "gpio32", "gpio33";
				function = "qup9";
			};

			qup_i2c10_data_clk: qup-i2c10-data-clk-state {
				pins = "gpio36", "gpio37";
				function = "qup10";
			};

			qup_i2c11_data_clk: qup-i2c11-data-clk-state {
				pins = "gpio40", "gpio41";
				function = "qup11";
			};

			qup_i2c12_data_clk: qup-i2c12-data-clk-state {
				pins = "gpio44", "gpio45";
				function = "qup12";
			};

			qup_i2c13_data_clk: qup-i2c13-data-clk-state {
				pins = "gpio48", "gpio49";
				function = "qup13";
				drive-strength = <2>;
				bias-pull-up;
			};

			qup_i2c14_data_clk: qup-i2c14-data-clk-state {
				pins = "gpio52", "gpio53";
				function = "qup14";
				drive-strength = <2>;
				bias-pull-up;
			};

			qup_i2c15_data_clk: qup-i2c15-data-clk-state {
				pins = "gpio56", "gpio57";
				function = "qup15";
			};

			qup_i2c16_data_clk: qup-i2c16-data-clk-state {
				pins = "gpio60", "gpio61";
				function = "qup16";
			};

			qup_i2c17_data_clk: qup-i2c17-data-clk-state {
				pins = "gpio64", "gpio65";
				function = "qup17";
			};

			qup_i2c18_data_clk: qup-i2c18-data-clk-state {
				pins = "gpio68", "gpio69";
				function = "qup18";
			};

			qup_i2c19_data_clk: qup-i2c19-data-clk-state {
				pins = "gpio72", "gpio73";
				function = "qup19";
			};

			qup_i2c20_data_clk: qup-i2c20-data-clk-state {
				pins = "gpio76", "gpio77";
				function = "qup20";
			};

			qup_i2c21_data_clk: qup-i2c21-data-clk-state {
				pins = "gpio80", "gpio81";
				function = "qup21";
			};

			qup_spi0_cs: qup-spi0-cs-state {
				pins = "gpio3";
				function = "qup0";
			};

			qup_spi0_data_clk: qup-spi0-data-clk-state {
				pins = "gpio0", "gpio1", "gpio2";
				function = "qup0";
			};

			qup_spi1_cs: qup-spi1-cs-state {
				pins = "gpio7";
				function = "qup1";
			};

			qup_spi1_data_clk: qup-spi1-data-clk-state {
				pins = "gpio4", "gpio5", "gpio6";
				function = "qup1";
			};

			qup_spi2_cs: qup-spi2-cs-state {
				pins = "gpio11";
				function = "qup2";
			};

			qup_spi2_data_clk: qup-spi2-data-clk-state {
				pins = "gpio8", "gpio9", "gpio10";
				function = "qup2";
			};

			qup_uart3_tx: qup-uart3-tx-state {
				pins = "gpio22";
				function = "qup3";
				drive-strength = <2>;
				bias-disable;
			};

			qup_uart3_rx: qup-uart3-rx-state {
				pins = "gpio23";
				function = "qup3";
				drive-strength = <2>;
				bias-disable;
			};

			qup_spi4_cs: qup-spi4-cs-state {
				pins = "gpio19";
				function = "qup4";
				drive-strength = <6>;
				bias-disable;
			};

			qup_spi4_data_clk: qup-spi4-data-clk-state {
				pins = "gpio16", "gpio17", "gpio18";
				function = "qup4";
			};

			qup_spi5_cs: qup-spi5-cs-state {
				pins = "gpio85";
				function = "qup5";
			};

			qup_spi5_data_clk: qup-spi5-data-clk-state {
				pins = "gpio206", "gpio207", "gpio84";
				function = "qup5";
			};

			qup_spi6_cs: qup-spi6-cs-state {
				pins = "gpio23";
				function = "qup6";
			};

			qup_spi6_data_clk: qup-spi6-data-clk-state {
				pins = "gpio20", "gpio21", "gpio22";
				function = "qup6";
			};

			qup_spi8_cs: qup-spi8-cs-state {
				pins = "gpio31";
				function = "qup8";
			};

			qup_spi8_data_clk: qup-spi8-data-clk-state {
				pins = "gpio28", "gpio29", "gpio30";
				function = "qup8";
			};

			qup_spi9_cs: qup-spi9-cs-state {
				pins = "gpio35";
				function = "qup9";
			};

			qup_spi9_data_clk: qup-spi9-data-clk-state {
				pins = "gpio32", "gpio33", "gpio34";
				function = "qup9";
			};

			qup_spi10_cs: qup-spi10-cs-state {
				pins = "gpio39";
				function = "qup10";
			};

			qup_spi10_data_clk: qup-spi10-data-clk-state {
				pins = "gpio36", "gpio37", "gpio38";
				function = "qup10";
			};

			qup_spi11_cs: qup-spi11-cs-state {
				pins = "gpio43";
				function = "qup11";
			};

			qup_spi11_data_clk: qup-spi11-data-clk-state {
				pins = "gpio40", "gpio41", "gpio42";
				function = "qup11";
			};

			qup_spi12_cs: qup-spi12-cs-state {
				pins = "gpio47";
				function = "qup12";
			};

			qup_spi12_data_clk: qup-spi12-data-clk-state {
				pins = "gpio44", "gpio45", "gpio46";
				function = "qup12";
			};

			qup_spi13_cs: qup-spi13-cs-state {
				pins = "gpio51";
				function = "qup13";
			};

			qup_spi13_data_clk: qup-spi13-data-clk-state {
				pins = "gpio48", "gpio49", "gpio50";
				function = "qup13";
			};

			qup_spi14_cs: qup-spi14-cs-state {
				pins = "gpio55";
				function = "qup14";
			};

			qup_spi14_data_clk: qup-spi14-data-clk-state {
				pins = "gpio52", "gpio53", "gpio54";
				function = "qup14";
			};

			qup_spi15_cs: qup-spi15-cs-state {
				pins = "gpio59";
				function = "qup15";
			};

			qup_spi15_data_clk: qup-spi15-data-clk-state {
				pins = "gpio56", "gpio57", "gpio58";
				function = "qup15";
			};

			qup_spi16_cs: qup-spi16-cs-state {
				pins = "gpio63";
				function = "qup16";
			};

			qup_spi16_data_clk: qup-spi16-data-clk-state {
				pins = "gpio60", "gpio61", "gpio62";
				function = "qup16";
			};

			qup_spi17_cs: qup-spi17-cs-state {
				pins = "gpio67";
				function = "qup17";
			};

			qup_spi17_data_clk: qup-spi17-data-clk-state {
				pins = "gpio64", "gpio65", "gpio66";
				function = "qup17";
			};

			qup_spi18_cs: qup-spi18-cs-state {
				pins = "gpio71";
				function = "qup18";
				drive-strength = <6>;
				bias-disable;
			};

			qup_spi18_data_clk: qup-spi18-data-clk-state {
				pins = "gpio68", "gpio69", "gpio70";
				function = "qup18";
				drive-strength = <6>;
				bias-disable;
			};

			qup_spi19_cs: qup-spi19-cs-state {
				pins = "gpio75";
				function = "qup19";
				drive-strength = <6>;
				bias-disable;
			};

			qup_spi19_data_clk: qup-spi19-data-clk-state {
				pins = "gpio72", "gpio73", "gpio74";
				function = "qup19";
				drive-strength = <6>;
				bias-disable;
			};

			qup_spi20_cs: qup-spi20-cs-state {
				pins = "gpio79";
				function = "qup20";
			};

			qup_spi20_data_clk: qup-spi20-data-clk-state {
				pins = "gpio76", "gpio77", "gpio78";
				function = "qup20";
			};

			qup_spi21_cs: qup-spi21-cs-state {
				pins = "gpio83";
				function = "qup21";
			};

			qup_spi21_data_clk: qup-spi21-data-clk-state {
				pins = "gpio80", "gpio81", "gpio82";
				function = "qup21";
			};
		};

		tsens0: thermal-sensor@c263000 {
			compatible = "qcom,tsens-v2";
			reg = <0 0x0c263000 0 0x1000>, /* TM */
			      <0 0x0c222000 0 0x1000>; /* SROT */
			#qcom,sensors = <16>;
			interrupts = <GIC_SPI 506 IRQ_TYPE_LEVEL_HIGH>,
				     <GIC_SPI 508 IRQ_TYPE_LEVEL_HIGH>;
			interrupt-names = "uplow", "critical";
			#thermal-sensor-cells = <1>;
		};

		tsens1: thermal-sensor@c265000 {
			compatible = "qcom,tsens-v2";
			reg = <0 0x0c265000 0 0x1000>, /* TM */
			      <0 0x0c223000 0 0x1000>; /* SROT */
			#qcom,sensors = <16>;
			interrupts = <GIC_SPI 507 IRQ_TYPE_LEVEL_HIGH>,
				     <GIC_SPI 509 IRQ_TYPE_LEVEL_HIGH>;
			interrupt-names = "uplow", "critical";
			#thermal-sensor-cells = <1>;
		};

		sram@146aa000 {
			// TODO: add compatible to dt-bindings
			compatible = "qcom,sm7435-imem", "syscon", "simple-mfd";
			reg = <0 0x146aa000 0 0x1000>;
			ranges = <0 0 0x146aa000 0x1000>;

			#address-cells = <1>;
			#size-cells = <1>;

			pil-reloc@94c {
				compatible = "qcom,pil-reloc-info";
				reg = <0x94c 0xc8>;
			};
		};

		apps_smmu: iommu@15000000 {
			compatible = "qcom,smmu-500", "arm,mmu-500";
			reg = <0 0x15000000 0 0x100000>;
			#iommu-cells = <2>;
			#global-interrupts = <1>;
			interrupts = <GIC_SPI 65 IRQ_TYPE_LEVEL_HIGH>,
                                     <GIC_SPI 96 IRQ_TYPE_LEVEL_HIGH>,
                                     <GIC_SPI 670 IRQ_TYPE_LEVEL_HIGH>,
                                     <GIC_SPI 671 IRQ_TYPE_LEVEL_HIGH>,
                                     <GIC_SPI 97 IRQ_TYPE_LEVEL_HIGH>,
                                     <GIC_SPI 98 IRQ_TYPE_LEVEL_HIGH>,
                                     <GIC_SPI 99 IRQ_TYPE_LEVEL_HIGH>,
                                     <GIC_SPI 100 IRQ_TYPE_LEVEL_HIGH>,
                                     <GIC_SPI 101 IRQ_TYPE_LEVEL_HIGH>,
                                     <GIC_SPI 102 IRQ_TYPE_LEVEL_HIGH>,
                                     <GIC_SPI 103 IRQ_TYPE_LEVEL_HIGH>,
                                     <GIC_SPI 104 IRQ_TYPE_LEVEL_HIGH>,
                                     <GIC_SPI 105 IRQ_TYPE_LEVEL_HIGH>,
                                     <GIC_SPI 106 IRQ_TYPE_LEVEL_HIGH>,
                                     <GIC_SPI 107 IRQ_TYPE_LEVEL_HIGH>,
                                     <GIC_SPI 108 IRQ_TYPE_LEVEL_HIGH>,
                                     <GIC_SPI 109 IRQ_TYPE_LEVEL_HIGH>,
                                     <GIC_SPI 110 IRQ_TYPE_LEVEL_HIGH>,
                                     <GIC_SPI 111 IRQ_TYPE_LEVEL_HIGH>,
                                     <GIC_SPI 112 IRQ_TYPE_LEVEL_HIGH>,
                                     <GIC_SPI 113 IRQ_TYPE_LEVEL_HIGH>,
                                     <GIC_SPI 114 IRQ_TYPE_LEVEL_HIGH>,
                                     <GIC_SPI 115 IRQ_TYPE_LEVEL_HIGH>,
                                     <GIC_SPI 116 IRQ_TYPE_LEVEL_HIGH>,
                                     <GIC_SPI 117 IRQ_TYPE_LEVEL_HIGH>,
                                     <GIC_SPI 118 IRQ_TYPE_LEVEL_HIGH>,
                                     <GIC_SPI 181 IRQ_TYPE_LEVEL_HIGH>,
                                     <GIC_SPI 182 IRQ_TYPE_LEVEL_HIGH>,
                                     <GIC_SPI 183 IRQ_TYPE_LEVEL_HIGH>,
                                     <GIC_SPI 184 IRQ_TYPE_LEVEL_HIGH>,
                                     <GIC_SPI 185 IRQ_TYPE_LEVEL_HIGH>,
                                     <GIC_SPI 186 IRQ_TYPE_LEVEL_HIGH>,
                                     <GIC_SPI 187 IRQ_TYPE_LEVEL_HIGH>,
                                     <GIC_SPI 188 IRQ_TYPE_LEVEL_HIGH>,
                                     <GIC_SPI 189 IRQ_TYPE_LEVEL_HIGH>,
                                     <GIC_SPI 190 IRQ_TYPE_LEVEL_HIGH>,
                                     <GIC_SPI 191 IRQ_TYPE_LEVEL_HIGH>,
                                     <GIC_SPI 192 IRQ_TYPE_LEVEL_HIGH>,
                                     <GIC_SPI 315 IRQ_TYPE_LEVEL_HIGH>,
                                     <GIC_SPI 316 IRQ_TYPE_LEVEL_HIGH>,
                                     <GIC_SPI 317 IRQ_TYPE_LEVEL_HIGH>,
                                     <GIC_SPI 318 IRQ_TYPE_LEVEL_HIGH>,
                                     <GIC_SPI 319 IRQ_TYPE_LEVEL_HIGH>,
                                     <GIC_SPI 320 IRQ_TYPE_LEVEL_HIGH>,
                                     <GIC_SPI 321 IRQ_TYPE_LEVEL_HIGH>,
                                     <GIC_SPI 322 IRQ_TYPE_LEVEL_HIGH>,
                                     <GIC_SPI 323 IRQ_TYPE_LEVEL_HIGH>,
                                     <GIC_SPI 324 IRQ_TYPE_LEVEL_HIGH>,
                                     <GIC_SPI 325 IRQ_TYPE_LEVEL_HIGH>,
                                     <GIC_SPI 326 IRQ_TYPE_LEVEL_HIGH>,
                                     <GIC_SPI 327 IRQ_TYPE_LEVEL_HIGH>,
                                     <GIC_SPI 328 IRQ_TYPE_LEVEL_HIGH>,
                                     <GIC_SPI 329 IRQ_TYPE_LEVEL_HIGH>,
                                     <GIC_SPI 330 IRQ_TYPE_LEVEL_HIGH>,
                                     <GIC_SPI 331 IRQ_TYPE_LEVEL_HIGH>,
                                     <GIC_SPI 332 IRQ_TYPE_LEVEL_HIGH>,
                                     <GIC_SPI 333 IRQ_TYPE_LEVEL_HIGH>,
                                     <GIC_SPI 334 IRQ_TYPE_LEVEL_HIGH>,
                                     <GIC_SPI 335 IRQ_TYPE_LEVEL_HIGH>,
                                     <GIC_SPI 336 IRQ_TYPE_LEVEL_HIGH>,
                                     <GIC_SPI 337 IRQ_TYPE_LEVEL_HIGH>,
                                     <GIC_SPI 338 IRQ_TYPE_LEVEL_HIGH>,
                                     <GIC_SPI 339 IRQ_TYPE_LEVEL_HIGH>,
                                     <GIC_SPI 340 IRQ_TYPE_LEVEL_HIGH>,
                                     <GIC_SPI 341 IRQ_TYPE_LEVEL_HIGH>,
                                     <GIC_SPI 342 IRQ_TYPE_LEVEL_HIGH>,
                                     <GIC_SPI 343 IRQ_TYPE_LEVEL_HIGH>,
                                     <GIC_SPI 344 IRQ_TYPE_LEVEL_HIGH>,
                                     <GIC_SPI 345 IRQ_TYPE_LEVEL_HIGH>,
                                     <GIC_SPI 395 IRQ_TYPE_LEVEL_HIGH>,
                                     <GIC_SPI 396 IRQ_TYPE_LEVEL_HIGH>,
                                     <GIC_SPI 397 IRQ_TYPE_LEVEL_HIGH>,
                                     <GIC_SPI 398 IRQ_TYPE_LEVEL_HIGH>,
                                     <GIC_SPI 399 IRQ_TYPE_LEVEL_HIGH>,
                                     <GIC_SPI 400 IRQ_TYPE_LEVEL_HIGH>,
                                     <GIC_SPI 401 IRQ_TYPE_LEVEL_HIGH>,
                                     <GIC_SPI 402 IRQ_TYPE_LEVEL_HIGH>,
                                     <GIC_SPI 403 IRQ_TYPE_LEVEL_HIGH>,
                                     <GIC_SPI 404 IRQ_TYPE_LEVEL_HIGH>,
                                     <GIC_SPI 405 IRQ_TYPE_LEVEL_HIGH>,
                                     <GIC_SPI 406 IRQ_TYPE_LEVEL_HIGH>,
                                     <GIC_SPI 407 IRQ_TYPE_LEVEL_HIGH>,
                                     <GIC_SPI 408 IRQ_TYPE_LEVEL_HIGH>,
                                     <GIC_SPI 409 IRQ_TYPE_LEVEL_HIGH>,
                                     <GIC_SPI 412 IRQ_TYPE_LEVEL_HIGH>,
                                     <GIC_SPI 418 IRQ_TYPE_LEVEL_HIGH>,
                                     <GIC_SPI 419 IRQ_TYPE_LEVEL_HIGH>,
                                     <GIC_SPI 421 IRQ_TYPE_LEVEL_HIGH>,
                                     <GIC_SPI 706 IRQ_TYPE_LEVEL_HIGH>,
                                     <GIC_SPI 423 IRQ_TYPE_LEVEL_HIGH>,
                                     <GIC_SPI 424 IRQ_TYPE_LEVEL_HIGH>,
                                     <GIC_SPI 425 IRQ_TYPE_LEVEL_HIGH>,
                                     <GIC_SPI 689 IRQ_TYPE_LEVEL_HIGH>,
                                     <GIC_SPI 690 IRQ_TYPE_LEVEL_HIGH>,
                                     <GIC_SPI 691 IRQ_TYPE_LEVEL_HIGH>,
                                     <GIC_SPI 692 IRQ_TYPE_LEVEL_HIGH>,
                                     <GIC_SPI 693 IRQ_TYPE_LEVEL_HIGH>;
			dma-coherent;
		};

		intc: interrupt-controller@17100000 {
			compatible = "arm,gic-v3";
			#interrupt-cells = <3>;
			interrupt-controller;
			#redistributor-regions = <1>;
			redistributor-stride = <0x0 0x20000>;
			reg = <0x0 0x17200000 0x0 0x10000>,     /* GICD */
			      <0x0 0x17260000 0x0 0x100000>;    /* GICR * 8 */
			interrupts = <GIC_PPI 9 IRQ_TYPE_LEVEL_HIGH>;
			#address-cells = <2>;
			#size-cells = <2>;
			ranges;
		};

		timer@17420000 {
			compatible = "arm,armv7-timer-mem";
			#address-cells = <1>;
			#size-cells = <1>;
			ranges = <0 0 0 0x20000000>;
			reg = <0x0 0x17420000 0x0 0x1000>;
			clock-frequency = <19200000>;

			frame@17421000 {
				frame-number = <0>;
				interrupts = <GIC_SPI 8 IRQ_TYPE_LEVEL_HIGH>,
					     <GIC_SPI 6 IRQ_TYPE_LEVEL_HIGH>;
				reg = <0x17421000 0x1000>,
				      <0x17422000 0x1000>;
			};

			frame@17423000 {
				frame-number = <1>;
				interrupts = <GIC_SPI 9 IRQ_TYPE_LEVEL_HIGH>;
				reg = <0x17423000 0x1000>;
				status = "disabled";
			};

			frame@17425000 {
				frame-number = <2>;
				interrupts = <GIC_SPI 10 IRQ_TYPE_LEVEL_HIGH>;
				reg = <0x17425000 0x1000>;
				status = "disabled";
			};

			frame@17427000 {
				frame-number = <3>;
				interrupts = <GIC_SPI 11 IRQ_TYPE_LEVEL_HIGH>;
				reg = <0x17427000 0x1000>;
				status = "disabled";
			};

			frame@17429000 {
				frame-number = <4>;
				interrupts = <GIC_SPI 12 IRQ_TYPE_LEVEL_HIGH>;
				reg = <0x17429000 0x1000>;
				status = "disabled";
			};

			frame@1742b000 {
				frame-number = <5>;
				interrupts = <GIC_SPI 13 IRQ_TYPE_LEVEL_HIGH>;
				reg = <0x1742b000 0x1000>;
				status = "disabled";
			};

			frame@1742d000 {
				frame-number = <6>;
				interrupts = <GIC_SPI 14 IRQ_TYPE_LEVEL_HIGH>;
				reg = <0x1742d000 0x1000>;
				status = "disabled";
			};
		};

		apps_rsc: rsc@17a00000 {
			label = "apps_rsc";
			compatible = "qcom,rpmh-rsc";
			reg = <0x0 0x17a00000 0x0 0x10000>,
			      <0x0 0x17a10000 0x0 0x10000>,
			      <0x0 0x17a20000 0x0 0x10000>;
			reg-names = "drv-0", "drv-1", "drv-2";
			interrupts = <GIC_SPI 3 IRQ_TYPE_LEVEL_HIGH>,
				     <GIC_SPI 4 IRQ_TYPE_LEVEL_HIGH>,
				     <GIC_SPI 5 IRQ_TYPE_LEVEL_HIGH>;
			qcom,tcs-offset = <0xd00>;
			qcom,drv-id = <2>;
			qcom,tcs-config = <ACTIVE_TCS  3>, <SLEEP_TCS   2>,
					  <WAKE_TCS    2>, <CONTROL_TCS 0>;
			power-domains = <&cluster_pd>;

			apps_bcm_voter: bcm-voter {
				compatible = "qcom,bcm-voter";
			};

			rpmhcc: clock-controller {
				compatible = "qcom,sm7435-rpmh-clk";
				#clock-cells = <1>;
				clock-names = "xo";
				clocks = <&xo_board>;
			};

			rpmhpd: power-controller {
				compatible = "qcom,sm7435-rpmhpd";
				#power-domain-cells = <1>;
				operating-points-v2 = <&rpmhpd_opp_table>;

				// TODO: i hope the opp levels are correct :p
				rpmhpd_opp_table: opp-table {
					compatible = "operating-points-v2";

					rpmhpd_opp_ret: opp1 {
						opp-level = <RPMH_REGULATOR_LEVEL_RETENTION>;
					};

					rpmhpd_opp_min_svs: opp2 {
						opp-level = <RPMH_REGULATOR_LEVEL_MIN_SVS>;
					};

					rpmhpd_opp_low_svs_d1: opp3 {
						opp-level = <RPMH_REGULATOR_LEVEL_LOW_SVS_D1>;
					};

					rpmhpd_opp_low_svs: opp4 {
						opp-level = <RPMH_REGULATOR_LEVEL_LOW_SVS>;
					};

					rpmhpd_opp_low_svs_l1: opp5 {
						opp-level = <RPMH_REGULATOR_LEVEL_LOW_SVS_L1>;
					};

					rpmhpd_opp_svs: opp6 {
						opp-level = <RPMH_REGULATOR_LEVEL_SVS>;
					};

					rpmhpd_opp_svs_l0: opp7 {
						opp-level = <RPMH_REGULATOR_LEVEL_SVS_L0>;
					};

					rpmhpd_opp_svs_l1: opp8 {
						opp-level = <RPMH_REGULATOR_LEVEL_SVS_L1>;
					};

					rpmhpd_opp_svs_l2: opp9 {
						opp-level = <RPMH_REGULATOR_LEVEL_SVS_L2>;
					};

					rpmhpd_opp_nom: opp10 {
						opp-level = <RPMH_REGULATOR_LEVEL_NOM>;
					};

					rpmhpd_opp_nom_l1: opp11 {
						opp-level = <RPMH_REGULATOR_LEVEL_NOM_L1>;
					};

					rpmhpd_opp_nom_l2: opp12 {
						opp-level = <RPMH_REGULATOR_LEVEL_NOM_L2>;
					};

					rpmhpd_opp_turbo: opp13 {
						opp-level = <RPMH_REGULATOR_LEVEL_TURBO>;
					};

					rpmhpd_opp_turbo_l1: opp14 {
						opp-level = <RPMH_REGULATOR_LEVEL_TURBO_L1>;
					};
				};
			};
		};

		cpufreq_hw: cpufreq@17d91000 {
			compatible = "qcom,cpufreq-epss";
			reg = <0 0x17d91000 0 0x1000>,
			      <0 0x17d92000 0 0x1000>;
			reg-names = "freq-domain0", "freq-domain1";
			clocks = <&rpmhcc RPMH_CXO_CLK>, <&gcc GCC_GPLL0>;
			clock-names = "xo", "alternate";
			interrupts = <GIC_SPI 30 IRQ_TYPE_LEVEL_HIGH>,
				     <GIC_SPI 31 IRQ_TYPE_LEVEL_HIGH>;
			interrupt-names = "dcvsh-irq-0", "dcvsh-irq-1";
			#freq-domain-cells = <1>;
			#clock-cells = <1>;
		};

		gem_noc: interconnect@19100000 {
			compatible = "qcom,sm7435-gem-noc";
			reg = <0 0x19100000 0 0xbb800>;
			#interconnect-cells = <2>;
			qcom,bcm-voters = <&apps_bcm_voter>;
		};

		ufs_mem_hc: ufshc@1d84000 {
			compatible = "qcom,ufshc", "jedec,ufs-2.0";
			reg = <0 0x01d84000 0 0x3000>;
			interrupts = <GIC_SPI 265 IRQ_TYPE_LEVEL_HIGH>;
			phys = <&ufs_mem_phy>;
			phy-names = "ufsphy";
			lanes-per-direction = <2>;
			#reset-cells = <1>;
			resets = <&gcc GCC_UFS_PHY_BCR>;
			reset-names = "rst";

			// TODO
			//power-domains = <&gcc UFS_PHY_GDSC>;

			iommus = <&apps_smmu 0xe0 0x0>;
			dma-coherent;

			interconnects = <&aggre1_noc MASTER_UFS_MEM 0 &mc_virt SLAVE_EBI1 0>,
					<&gem_noc MASTER_APPSS_PROC 0>;
			interconnect-names = "ufs-ddr", "cpu-ufs";
			clock-names =
				"core_clk",
				"bus_aggr_clk",
				"iface_clk",
				"core_clk_unipro",
				"ref_clk",
				"tx_lane0_sync_clk",
				"rx_lane0_sync_clk",
				"rx_lane1_sync_clk";
			clocks =
				<&gcc GCC_UFS_PHY_AXI_CLK>,
				<&gcc GCC_AGGRE_UFS_PHY_AXI_CLK>,
				<&gcc GCC_UFS_PHY_AHB_CLK>,
				<&gcc GCC_UFS_PHY_UNIPRO_CORE_CLK>,
				<&rpmhcc RPMH_CXO_CLK>,
				<&gcc GCC_UFS_PHY_TX_SYMBOL_0_CLK>,
				<&gcc GCC_UFS_PHY_RX_SYMBOL_0_CLK>,
				<&gcc GCC_UFS_PHY_RX_SYMBOL_1_CLK>;
			freq-table-hz =
				<75000000 300000000>,
				<0 0>,
				<0 0>,
				<75000000 300000000>,
				<75000000 300000000>,
				<0 0>,
				<0 0>,
				<0 0>;
			qcom,ice = <&ice>;

			status = "disabled";
		};

		ufs_mem_phy: phy@1d87000 {
			compatible = "qcom,sm8450-qmp-ufs-phy";
			reg = <0 0x01d87000 0 0x1000>;

			clock-names = "ref", "ref_aux", "qref";
			clocks = <&rpmhcc RPMH_CXO_CLK>,
				 <&gcc GCC_UFS_PHY_PHY_AUX_CLK>,
				 <&gcc GCC_UFS_0_CLKREF_EN>;

			// TODO
			//power-domains = <&gcc UFS_PHY_GDSC>;

			resets = <&ufs_mem_hc 0>;
			reset-names = "ufsphy";

			#clock-cells = <1>;
			#phy-cells = <0>;

			status = "disabled";
		};

		ice: crypto@1d88000 {
			compatible = "qcom,sm8450-inline-crypto-engine",
				     "qcom,inline-crypto-engine";
			reg = <0 0x01d88000 0 0x8000>;
			clocks = <&gcc GCC_UFS_PHY_ICE_CORE_CLK>;
		};

		cryptobam: dma-controller@1dc4000 {
			compatible = "qcom,bam-v1.7.4", "qcom,bam-v1.7.0";
			reg = <0 0x01dc4000 0 0x28000>;
			interrupts = <GIC_SPI 272 IRQ_TYPE_LEVEL_HIGH>;
			#dma-cells = <1>;
			qcom,ee = <0>;
			qcom,controlled-remotely;
			iommus = <&apps_smmu 0x484 0x11>,
				 <&apps_smmu 0x488 0x0>,
				 <&apps_smmu 0x498 0x5>,
				 <&apps_smmu 0x49a 0x0>,
				 <&apps_smmu 0x49f 0x0>;
		};

		crypto: crypto@1dfa000 {
			compatible = "qcom,qce";
			reg = <0 0x01dfa000 0 0x6000>;
			dmas = <&cryptobam 4>, <&cryptobam 5>;
			dma-names = "rx", "tx";
			iommus = <&apps_smmu 0x484 0x11>,
				 <&apps_smmu 0x488 0x0>,
				 <&apps_smmu 0x498 0x5>,
				 <&apps_smmu 0x49a 0x0>,
				 <&apps_smmu 0x49f 0x0>;
			interconnects = <&aggre2_noc MASTER_CRYPTO 0 &mc_virt SLAVE_EBI1 0>;
			interconnect-names = "memory";
		};

		sdhc_2: mmc@8804000 {
			compatible = "qcom,sdhci-msm-v5";
			reg = <0 0x08804000 0 0x1000>;

			interrupts = <GIC_SPI 207 IRQ_TYPE_LEVEL_HIGH>,
				     <GIC_SPI 223 IRQ_TYPE_LEVEL_HIGH>;
			interrupt-names = "hc_irq", "pwr_irq";

			clocks = <&gcc GCC_SDCC2_AHB_CLK>,
				 <&gcc GCC_SDCC2_APPS_CLK>,
				 <&rpmhcc RPMH_CXO_CLK>;
			clock-names = "iface", "core", "xo";
			resets = <&gcc GCC_SDCC2_BCR>;
			interconnects = <&aggre2_noc MASTER_SDCC_2 0 &mc_virt SLAVE_EBI1 0>,
					<&gem_noc MASTER_APPSS_PROC 0>;
			interconnect-names = "sdhc-ddr","cpu-sdhc";
			iommus = <&apps_smmu 0x4a0 0x0>;
			power-domains = <&rpmhpd RPMHPD_CX>;
			operating-points-v2 = <&sdhc2_opp_table>;
			bus-width = <4>;
			dma-coherent;

			/* Forbid SDR104/SDR50 - broken hw! */
			sdhci-caps-mask = <0x3 0x0>;

			status = "disabled";

			sdhc2_opp_table: opp-table {
				compatible = "operating-points-v2";

				opp-100000000 {
					opp-hz = /bits/ 64 <100000000>;
					required-opps = <&rpmhpd_opp_low_svs>;
				};

				opp-202000000 {
					opp-hz = /bits/ 64 <202000000>;
					required-opps = <&rpmhpd_opp_svs_l1>;
				};
			};
		};

		usb_1: usb@a6f8800 {
			compatible = "qcom,dwc3";
			// TODO: pong dts does not mention this either...
			reg = <0 0x0a6f8800 0 0x400>;
			status = "disabled";
			#address-cells = <2>;
			#size-cells = <2>;
			ranges;

			clocks = <&gcc GCC_CFG_NOC_USB3_PRIM_AXI_CLK>,
				 <&gcc GCC_USB30_PRIM_MASTER_CLK>,
				 <&gcc GCC_AGGRE_USB3_PRIM_AXI_CLK>,
				 <&gcc GCC_USB30_PRIM_SLEEP_CLK>,
				 <&gcc GCC_USB30_PRIM_MOCK_UTMI_CLK>,
				 <&gcc GCC_USB3_0_CLKREF_EN>;
			clock-names = "cfg_noc",
				      "core",
				      "iface",
				      "sleep",
				      "mock_utmi",
				      "xo";

			assigned-clocks = <&gcc GCC_USB30_PRIM_MOCK_UTMI_CLK>,
					  <&gcc GCC_USB30_PRIM_MASTER_CLK>;
			assigned-clock-rates = <19200000>, <200000000>;

			interrupts-extended = <&intc GIC_SPI 130 IRQ_TYPE_LEVEL_HIGH>,
					      <&intc GIC_SPI 131 IRQ_TYPE_LEVEL_HIGH>,
					      <&pdc 14 IRQ_TYPE_EDGE_BOTH>,
					      <&pdc 15 IRQ_TYPE_EDGE_BOTH>,
					      <&pdc 17 IRQ_TYPE_LEVEL_HIGH>;
			interrupt-names = "pwr_event",
					  "hs_phy_irq",
					  "dp_hs_phy_irq",
					  "dm_hs_phy_irq",
					  "ss_phy_irq";

			// TODO
			//power-domains = <&gcc USB30_PRIM_GDSC>;

			resets = <&gcc GCC_USB30_PRIM_BCR>;

			interconnects = <&aggre1_noc MASTER_USB3_0 0 &mc_virt SLAVE_EBI1 0>,
					<&gem_noc MASTER_APPSS_PROC 0>;
			interconnect-names = "usb-ddr", "apps-usb";

			/*usb_1_dwc3: usb@a600000 {
				compatible = "snps,dwc3";
				reg = <0 0x0a600000 0 0xcd00>;
				interrupts = <GIC_SPI 133 IRQ_TYPE_LEVEL_HIGH>;
				iommus = <&apps_smmu 0x0 0x0>;
				snps,dis_u2_susphy_quirk;
				snps,dis_enblslpm_quirk;
				snps,dis-u1-entry-quirk;
				snps,dis-u2-entry-quirk;
				// TODO USB3
				phys = <&usb_1_hsphy>;
				phy-names = "usb2-phy";

				ports {
					#address-cells = <1>;
					#size-cells = <0>;

					port@0 {
						reg = <0>;

						usb_1_dwc3_hs: endpoint {
						};
					};

					port@1 {
						reg = <1>;

						usb_1_dwc3_ss: endpoint {
							//remote-endpoint = <&usb_1_qmpphy_usb_ss_in>;
						};
					};
				};
			};*/
		};

		nsp_noc: interconnect@320c0000 {
			compatible = "qcom,sm7435-nsp-noc";
			reg = <0 0x320c0000 0 0x10000>;
			#interconnect-cells = <2>;
			qcom,bcm-voters = <&apps_bcm_voter>;
		};

		lpass_ag_noc: interconnect@3c40000 {
			compatible = "qcom,sm7435-lpass-ag-noc";
			reg = <0 0x03c40000 0 0x17200>;
			#interconnect-cells = <2>;
			qcom,bcm-voters = <&apps_bcm_voter>;
		};
	};

	thermal-zones {
		aoss0-thermal {
			thermal-sensors = <&tsens0 0>;

			trips {
				thermal-engine-config {
					temperature = <125000>;
					hysteresis = <1000>;
					type = "passive";
				};

				reset-mon-cfg {
					temperature = <115000>;
					hysteresis = <5000>;
					type = "passive";
				};
			};
		};

		cpuss0-thermal {
			thermal-sensors = <&tsens0 1>;

			trips {
				thermal-engine-config {
					temperature = <125000>;
					hysteresis = <1000>;
					type = "passive";
				};

				reset-mon-cfg {
					temperature = <115000>;
					hysteresis = <5000>;
					type = "passive";
				};
			};
		};

		cpuss1-thermal {
			thermal-sensors = <&tsens0 2>;

			trips {
				thermal-engine-config {
					temperature = <125000>;
					hysteresis = <1000>;
					type = "passive";
				};

				reset-mon-cfg {
					temperature = <115000>;
					hysteresis = <5000>;
					type = "passive";
				};
			};
		};

		cpu4-top-thermal {
			thermal-sensors = <&tsens0 3>;

			trips {
				cpu4_top_alert0: trip-point0 {
					temperature = <90000>;
					hysteresis = <2000>;
					type = "passive";
				};

				cpu4_top_alert1: trip-point1 {
					temperature = <95000>;
					hysteresis = <2000>;
					type = "passive";
				};

				cpu4_top_crit: cpu-crit {
					temperature = <110000>;
					hysteresis = <1000>;
					type = "critical";
				};
			};
		};

		cpu4-bottom-thermal {
			thermal-sensors = <&tsens0 4>;

			trips {
				cpu4_bottom_alert0: trip-point0 {
					temperature = <90000>;
					hysteresis = <2000>;
					type = "passive";
				};

				cpu4_bottom_alert1: trip-point1 {
					temperature = <95000>;
					hysteresis = <2000>;
					type = "passive";
				};

				cpu4_bottom_crit: cpu-crit {
					temperature = <110000>;
					hysteresis = <1000>;
					type = "critical";
				};
			};
		};

		cpu5-top-thermal {
			polling-delay-passive = <10>;
			thermal-sensors = <&tsens0 5>;

			trips {
				cpu5_top_alert0: trip-point0 {
					temperature = <90000>;
					hysteresis = <2000>;
					type = "passive";
				};

				cpu5_top_alert1: trip-point1 {
					temperature = <95000>;
					hysteresis = <2000>;
					type = "passive";
				};

				cpu5_top_crit: cpu-crit {
					temperature = <110000>;
					hysteresis = <1000>;
					type = "critical";
				};
			};
		};

		cpu5-bottom-thermal {
			polling-delay-passive = <10>;
			thermal-sensors = <&tsens0 6>;

			trips {
				cpu5_bottom_alert0: trip-point0 {
					temperature = <90000>;
					hysteresis = <2000>;
					type = "passive";
				};

				cpu5_bottom_alert1: trip-point1 {
					temperature = <95000>;
					hysteresis = <2000>;
					type = "passive";
				};

				cpu5_bottom_crit: cpu-crit {
					temperature = <110000>;
					hysteresis = <1000>;
					type = "critical";
				};
			};
		};

		cpu6-top-thermal {
			polling-delay-passive = <10>;
			thermal-sensors = <&tsens0 7>;

			trips {
				cpu6_top_alert0: trip-point0 {
					temperature = <90000>;
					hysteresis = <2000>;
					type = "passive";
				};

				cpu6_top_alert1: trip-point1 {
					temperature = <95000>;
					hysteresis = <2000>;
					type = "passive";
				};

				cpu6_top_crit: cpu-crit {
					temperature = <110000>;
					hysteresis = <1000>;
					type = "critical";
				};
			};
		};

		cpu6-bottom-thermal {
			polling-delay-passive = <10>;
			thermal-sensors = <&tsens0 8>;

			trips {
				cpu6_bottom_alert0: trip-point0 {
					temperature = <90000>;
					hysteresis = <2000>;
					type = "passive";
				};

				cpu6_bottom_alert1: trip-point1 {
					temperature = <95000>;
					hysteresis = <2000>;
					type = "passive";
				};

				cpu6_bottom_crit: cpu-crit {
					temperature = <110000>;
					hysteresis = <1000>;
					type = "critical";
				};
			};
		};

		cpu7-top-thermal {
			polling-delay-passive = <10>;
			thermal-sensors = <&tsens0 9>;

			trips {
				cpu7_top_alert0: trip-point0 {
					temperature = <90000>;
					hysteresis = <2000>;
					type = "passive";
				};

				cpu7_top_alert1: trip-point1 {
					temperature = <95000>;
					hysteresis = <2000>;
					type = "passive";
				};

				cpu7_top_crit: cpu-crit {
					temperature = <110000>;
					hysteresis = <1000>;
					type = "critical";
				};
			};
		};

		cpu7-bottom-thermal {
			polling-delay-passive = <10>;
			thermal-sensors = <&tsens0 10>;

			trips {
				cpu7_bottom_alert0: trip-point0 {
					temperature = <90000>;
					hysteresis = <2000>;
					type = "passive";
				};

				cpu7_bottom_alert1: trip-point1 {
					temperature = <95000>;
					hysteresis = <2000>;
					type = "passive";
				};

				cpu7_bottom_crit: cpu-crit {
					temperature = <110000>;
					hysteresis = <1000>;
					type = "critical";
				};
			};
		};

		// TODO verify trips
		/*gpu-top-thermal {
			polling-delay-passive = <10>;

			thermal-sensors = <&tsens0 11>;

			cooling-maps {
				map0 {
					trip = <&gpu_top_alert0>;
					cooling-device = <&gpu THERMAL_NO_LIMIT THERMAL_NO_LIMIT>;
				};
			};

			trips {
				gpu_top_alert0: trip-point0 {
					temperature = <85000>;
					hysteresis = <1000>;
					type = "passive";
				};

				trip-point1 {
					temperature = <90000>;
					hysteresis = <1000>;
					type = "hot";
				};

				trip-point2 {
					temperature = <110000>;
					hysteresis = <1000>;
					type = "critical";
				};
			};
		};

		gpu-bottom-thermal {
			polling-delay-passive = <10>;

			thermal-sensors = <&tsens0 12>;

			cooling-maps {
				map0 {
					trip = <&gpu_bottom_alert0>;
					cooling-device = <&gpu THERMAL_NO_LIMIT THERMAL_NO_LIMIT>;
				};
			};

			trips {
				gpu_bottom_alert0: trip-point0 {
					temperature = <85000>;
					hysteresis = <1000>;
					type = "passive";
				};

				trip-point1 {
					temperature = <90000>;
					hysteresis = <1000>;
					type = "hot";
				};

				trip-point2 {
					temperature = <110000>;
					hysteresis = <1000>;
					type = "critical";
				};
			};
		};*/

		aoss1-thermal {
			thermal-sensors = <&tsens1 0>;

			trips {
				thermal-engine-config {
					temperature = <125000>;
					hysteresis = <1000>;
					type = "passive";
				};

				reset-mon-cfg {
					temperature = <115000>;
					hysteresis = <5000>;
					type = "passive";
				};
			};
		};

		cpu0-thermal {
			thermal-sensors = <&tsens1 1>;

			trips {
				cpu0_alert0: trip-point0 {
					temperature = <90000>;
					hysteresis = <2000>;
					type = "passive";
				};

				cpu0_alert1: trip-point1 {
					temperature = <95000>;
					hysteresis = <2000>;
					type = "passive";
				};

				cpu0_crit: cpu-crit {
					temperature = <110000>;
					hysteresis = <1000>;
					type = "critical";
				};
			};
		};

		cpu1-thermal {
			thermal-sensors = <&tsens1 2>;

			trips {
				cpu1_alert0: trip-point0 {
					temperature = <90000>;
					hysteresis = <2000>;
					type = "passive";
				};

				cpu1_alert1: trip-point1 {
					temperature = <95000>;
					hysteresis = <2000>;
					type = "passive";
				};

				cpu1_crit: cpu-crit {
					temperature = <110000>;
					hysteresis = <1000>;
					type = "critical";
				};
			};
		};

		cpu2-thermal {
			thermal-sensors = <&tsens1 3>;

			trips {
				cpu2_alert0: trip-point0 {
					temperature = <90000>;
					hysteresis = <2000>;
					type = "passive";
				};

				cpu2_alert1: trip-point1 {
					temperature = <95000>;
					hysteresis = <2000>;
					type = "passive";
				};

				cpu2_crit: cpu-crit {
					temperature = <110000>;
					hysteresis = <1000>;
					type = "critical";
				};
			};
		};

		cpu3-thermal {
			thermal-sensors = <&tsens1 4>;

			trips {
				cpu3_alert0: trip-point0 {
					temperature = <90000>;
					hysteresis = <2000>;
					type = "passive";
				};

				cpu3_alert1: trip-point1 {
					temperature = <95000>;
					hysteresis = <2000>;
					type = "passive";
				};

				cpu3_crit: cpu-crit {
					temperature = <110000>;
					hysteresis = <1000>;
					type = "critical";
				};
			};
		};

		cdsp0-thermal {
			polling-delay-passive = <10>;

			thermal-sensors = <&tsens1 5>;

			trips {
				thermal-engine-config {
					temperature = <125000>;
					hysteresis = <1000>;
					type = "passive";
				};

				thermal-hal-config {
					temperature = <125000>;
					hysteresis = <1000>;
					type = "passive";
				};

				reset-mon-cfg {
					temperature = <115000>;
					hysteresis = <5000>;
					type = "passive";
				};

				cdsp_0_config: junction-config {
					temperature = <95000>;
					hysteresis = <5000>;
					type = "passive";
				};
			};
		};

		cdsp1-thermal {
			polling-delay-passive = <10>;

			thermal-sensors = <&tsens1 6>;

			trips {
				thermal-engine-config {
					temperature = <125000>;
					hysteresis = <1000>;
					type = "passive";
				};

				thermal-hal-config {
					temperature = <125000>;
					hysteresis = <1000>;
					type = "passive";
				};

				reset-mon-cfg {
					temperature = <115000>;
					hysteresis = <5000>;
					type = "passive";
				};

				cdsp_1_config: junction-config {
					temperature = <95000>;
					hysteresis = <5000>;
					type = "passive";
				};
			};
		};

		video-thermal {
			thermal-sensors = <&tsens1 7>;

			trips {
				thermal-engine-config {
					temperature = <125000>;
					hysteresis = <1000>;
					type = "passive";
				};

				reset-mon-cfg {
					temperature = <115000>;
					hysteresis = <5000>;
					type = "passive";
				};
			};
		};

		mem-thermal {
			polling-delay-passive = <10>;

			thermal-sensors = <&tsens1 8>;

			trips {
				thermal-engine-config {
					temperature = <125000>;
					hysteresis = <1000>;
					type = "passive";
				};

				ddr_config0: ddr0-config {
					temperature = <90000>;
					hysteresis = <5000>;
					type = "passive";
				};

				reset-mon-cfg {
					temperature = <115000>;
					hysteresis = <5000>;
					type = "passive";
				};
			};
		};

		// todo find mdmss0 config in downstream?
		modem0-thermal {
			thermal-sensors = <&tsens1 9>;

			trips {
				thermal-engine-config {
					temperature = <125000>;
					hysteresis = <1000>;
					type = "passive";
				};

				mdmss0_config0: mdmss0-config0 {
					temperature = <102000>;
					hysteresis = <3000>;
					type = "passive";
				};

				mdmss0_config1: mdmss0-config1 {
					temperature = <105000>;
					hysteresis = <3000>;
					type = "passive";
				};

				reset-mon-cfg {
					temperature = <115000>;
					hysteresis = <5000>;
					type = "passive";
				};
			};
		};

		modem1-thermal {
			thermal-sensors = <&tsens1 10>;

			trips {
				thermal-engine-config {
					temperature = <125000>;
					hysteresis = <1000>;
					type = "passive";
				};

				mdmss1_config0: mdmss1-config0 {
					temperature = <102000>;
					hysteresis = <3000>;
					type = "passive";
				};

				mdmss1_config1: mdmss1-config1 {
					temperature = <105000>;
					hysteresis = <3000>;
					type = "passive";
				};

				reset-mon-cfg {
					temperature = <115000>;
					hysteresis = <5000>;
					type = "passive";
				};
			};
		};

		modem2-thermal {
			thermal-sensors = <&tsens1 11>;

			trips {
				thermal-engine-config {
					temperature = <125000>;
					hysteresis = <1000>;
					type = "passive";
				};

				mdmss2_config0: mdmss2-config0 {
					temperature = <102000>;
					hysteresis = <3000>;
					type = "passive";
				};

				mdmss2_config1: mdmss2-config1 {
					temperature = <105000>;
					hysteresis = <3000>;
					type = "passive";
				};

				reset-mon-cfg {
					temperature = <115000>;
					hysteresis = <5000>;
					type = "passive";
				};
			};
		};

		modem3-thermal {
			thermal-sensors = <&tsens1 12>;

			trips {
				thermal-engine-config {
					temperature = <125000>;
					hysteresis = <1000>;
					type = "passive";
				};

				mdmss3_config0: mdmss3-config0 {
					temperature = <102000>;
					hysteresis = <3000>;
					type = "passive";
				};

				mdmss3_config1: mdmss3-config1 {
					temperature = <105000>;
					hysteresis = <3000>;
					type = "passive";
				};

				reset-mon-cfg {
					temperature = <115000>;
					hysteresis = <5000>;
					type = "passive";
				};
			};
		};

		camera0-thermal {
			thermal-sensors = <&tsens1 13>;

			trips {
				thermal-engine-config {
					temperature = <125000>;
					hysteresis = <1000>;
					type = "passive";
				};

				reset-mon-cfg {
					temperature = <115000>;
					hysteresis = <5000>;
					type = "passive";
				};
			};
		};
	};

	timer {
		compatible = "arm,armv8-timer";
		interrupts = <GIC_PPI 13 (GIC_CPU_MASK_SIMPLE(8) | IRQ_TYPE_LEVEL_LOW)>,
			     <GIC_PPI 14 (GIC_CPU_MASK_SIMPLE(8) | IRQ_TYPE_LEVEL_LOW)>,
			     <GIC_PPI 11 (GIC_CPU_MASK_SIMPLE(8) | IRQ_TYPE_LEVEL_LOW)>,
			     <GIC_PPI 12 (GIC_CPU_MASK_SIMPLE(8) | IRQ_TYPE_LEVEL_LOW)>;
			     // TODO: qcom has last int number 10
		clock-frequency = <19200000>;
	};
};
